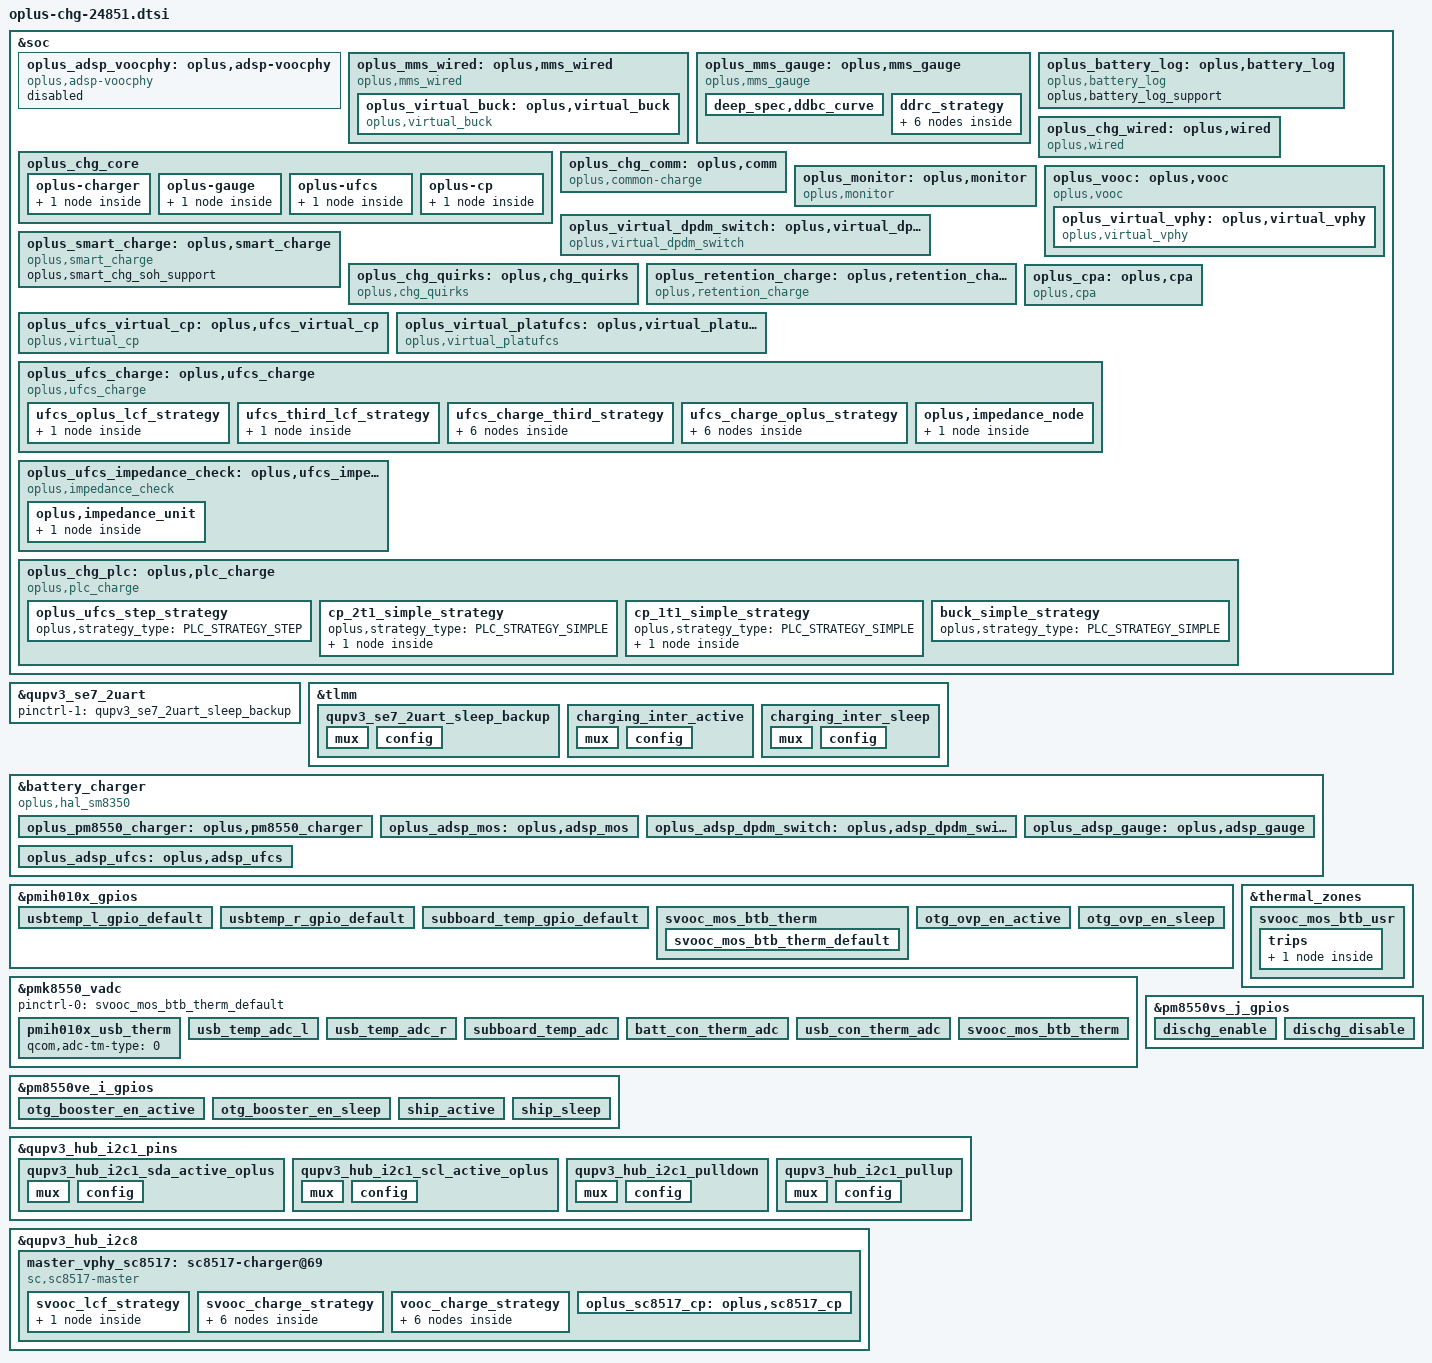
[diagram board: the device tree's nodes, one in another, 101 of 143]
//ifdef OPLUS_FEATURE_CHG_BASIC
//BSP.CHG.Basic, 2023/04/19, sjc Add for charging

#include "oplus-chg-8750.h.dtsi"

/*
 * NOTICE:
 * sector 1: wired charging
 * sector 2: ufcs
 * sector 3: pps
 */

//#ifdef OPLUS_FEATURE_CHG_BASIC /* BSP.CHG.Basic, 2023/04/19, sjc Add for wired charging */
//for wired charging config
&soc {
	oplus_adsp_voocphy: oplus,adsp-voocphy {
		status = "disabled";
		compatible = "oplus,adsp-voocphy";
	};

	oplus_mms_wired: oplus,mms_wired {
		compatible = "oplus,mms_wired";
		oplus,buck_ic = <&oplus_virtual_buck>;
		oplus,voocphy_ic = <&oplus_virtual_vphy>;

		oplus,adc_info_name = "855";
		oplus,topic-update-interval = <5000>;
		high-temp-scheme;

		oplus,support_usbtemp_protect_v2;
		oplus_spec,usbtemp_batt_temp_low = <50>;
		oplus_spec,usbtemp_batt_temp_high = <50>;
		oplus_spec,usbtemp_batt_temp_over_hot = <60>;
		oplus_spec,usbtemp_ntc_temp_low = <57>;
		oplus_spec,usbtemp_ntc_temp_high = <69>;
		oplus_spec,usbtemp_temp_gap_low_with_batt_temp = <7>;
		oplus_spec,usbtemp_temp_gap_with_batt_temp_in_over_hot = <15>;
		oplus_spec,usbtemp_temp_gap_high_with_batt_temp = <12>;
		oplus_spec,usbtemp_temp_gap_low_without_batt_temp = <12>;
		oplus_spec,usbtemp_temp_gap_high_without_batt_temp = <24>;
		oplus_spec,usbtemp_rise_fast_temp_low = <3>;
		oplus_spec,usbtemp_rise_fast_temp_high = <3>;
		oplus_spec,usbtemp_rise_fast_temp_count_low = <30>;
		oplus_spec,usbtemp_rise_fast_temp_count_high = <20>;
		oplus_spec,usbtemp_cool_down_ntc_low = <54>;
		oplus_spec,usbtemp_cool_down_ntc_high = <65>;
		oplus_spec,usbtemp_cool_down_gap_low = <12>;
		oplus_spec,usbtemp_cool_down_gap_high = <20>;
		oplus_spec,usbtemp_cool_down_recover_ntc_low = <48>;
		oplus_spec,usbtemp_cool_down_recover_ntc_high = <60>;
		oplus_spec,usbtemp_cool_down_recover_gap_low = <6>;
		oplus_spec,usbtemp_cool_down_recover_gap_high = <15>;
		oplus_spec,usbtemp_otg_cc_boot_current_limit = <2000>;

		oplus,series_batt_buck_eis_current_rate = <2>;

		oplus_virtual_buck: oplus,virtual_buck {
			compatible = "oplus,virtual_buck";
			oplus,buck_ic = <&oplus_pm8550_charger>;
			oplus,buck_ic_index = <0>;
			oplus,buck_ic_connect = <OPLUS_CHG_IC_CONNECT_PARALLEL>;
			oplus,main_charger = <1>;
			oplus,buck_ic_current_ratio = <100>;
			oplus,buck_ic_func_group = <&plat_pm8550_groups>;

			oplus,ic_type = <OPLUS_CHG_IC_VIRTUAL_BUCK>;
			oplus,ic_index = <0>;

			oplus,dischg-gpio = <&pm8550vs_j_gpios 6 0x00>;
			oplus,ship-gpio = <&pm8550ve_i_gpios 7 0x00>;
			oplus,usbtemp_conversion_ratio = <10>;

			pinctrl-names = "usbtemp_l_gpio_default", "usbtemp_r_gpio_default",
						"dischg_enable", "dischg_disable",
						"ship_active", "ship_sleep";
			pinctrl-0 = <&usbtemp_l_gpio_default>;
			pinctrl-1 = <&usbtemp_r_gpio_default>;
			pinctrl-2 = <&dischg_enable>;
			pinctrl-3 = <&dischg_disable>;
			pinctrl-4 = <&ship_active>;
			pinctrl-5 = <&ship_sleep>;

			io-channels = <&pmk8550_vadc PMIH010X_ADC5_GEN4_AMUX1_GPIO6_100K_PU>,
					      <&pmk8550_vadc PMIH010X_ADC5_GEN4_AMUX5_GPIO18_100K_PU>;
			io-channel-names = "usb_temp_adc_l", "usb_temp_adc_r";

			oplus,uart_tx-gpio = <&tlmm 62 0x00>;
			oplus,uart_rx-gpio = <&tlmm 63 0x00>;
		};
	};
	oplus_mms_gauge: oplus,mms_gauge {
		compatible = "oplus,mms_gauge";
		oplus,gauge_ic = <&oplus_virtual_gauge>;
		oplus,topic-update-interval = <5000>;
		oplus,support_subboard_ntc;
		oplus,fcl_support;
		oplus,fcl_index = <0>;
		oplus,vb_offset = <0>;

		deep_spec,support;
		deep_spec,uv_thr = <2750>;
		deep_spec,count_thr = <50>;
		deep_spec,vbat_soc = <80>;
		deep_spec,count_step = <0 10 0
					350 12 1
					450 15 2
					530 20 3>;

		deep_spec,term_coeff = <2900 600 0
					3000 650 0
					3010 650 0
					3050 750 0
					3100 800 0
					3110 800 0
					3150 900 0
					3160 900 0
					3200 1000 0
					3210 1000 0
					3260 1100 0>;
		deep_spec,ddrc_strategy_name = "ddrc_curve_v2";
		deep_spec,volt_step = <20>;
		deep_spec,ddbc_curve {
			oplus,temp_type = <OPLUS_STRATEGY_USE_BATT_TEMP>;
			oplus,temp_range = <(-100) 0 200>;
			deep_spec,ddbc_temp_cold = <500 3250 5
						   10000 3200 2>;
			deep_spec,ddbc_temp_cool = <500 3250 5
						   10000 3200 2>;
			deep_spec,ddbc_temp_normal = <500 3250 5
						   10000 3200 2>;
			deep_spec,ddbc_temp_warm = <500 3250 5
						   10000 3200 2>;
		};
		ddrc_strategy {
			oplus,temp_type = <OPLUS_STRATEGY_USE_BATT_TEMP>;
			oplus,ratio_range = <20 30 50 70 90>;
			oplus,temp_range = <(-100) 0 100 200 350>;
			strategy_ratio_range_min {
				strategy_temp_0 =	<0 2753 3000 0
							300 2910 3100 1
							700 3010 3150 2
							1100 3061 3160 3
							1500 3111 3210 4
							1900 3161 3260 5>;
				strategy_temp_1 =	<0 2752 3100 0
							400 2910 3100 1
							900 3010 3150 2
							1400 3061 3160 3
							1900 3111 3210 4
							2400 3161 3260 5>;
				strategy_temp_2 =	<0 2752 3100 0
							400 2910 3100 1
							900 3010 3150 2
							1400 3061 3160 3
							1900 3111 3210 4
							2400 3161 3260 5>;
				strategy_temp_3 =	<0 2751 2950 0
							400 2911 3000 1
							900 3000 3010 2
							1400 3060 3110 3
							1900 3110 3160 4
							2400 3160 3210 5>;
				strategy_temp_4 =	<0 2750 2900 0
							400 2900 2910 1
							900 3000 3010 2
							1400 3050 3050 3
							1900 3100 3100 4
							2400 3150 3150 5>;
				strategy_temp_5 =	<0 2750 2900 0
							400 2900 2910 1
							900 3000 3010 2
							1400 3050 3050 3
							1900 3100 3100 4
							2400 3150 3150 5>;
			};
			strategy_ratio_range_low {
				strategy_temp_0 =	<0 2753 3000 0
							250 2910 3100 1
							550 3010 3150 2
							850 3110 3160 3
							1150 3160 3210 4
							1450 3210 3260 5>;
				strategy_temp_1 =	<0 2752 3100 0
							300 2910 3100 1
							700 3010 3150 2
							1100 3061 3160 3
							1500 3111 3210 4
							1900 3161 3260 5>;
				strategy_temp_2 =	<0 2752 3100 0
							300 2910 3100 1
							700 3010 3150 2
							1100 3061 3160 3
							1500 3111 3210 4
							1900 3161 3260 5>;
				strategy_temp_3 =	<0 2751 2950 0
							300 2911 3000 1
							700 3000 3010 2
							1100 3060 3110 3
							1500 3110 3160 4
							1900 3160 3210 5>;
				strategy_temp_4 =	<0 2750 2900 0
							300 2900 2910 1
							700 3000 3010 2
							1100 3050 3050 3
							1500 3100 3100 4
							1900 3150 3150 5>;
				strategy_temp_5 =	<0 2750 2900 0
							300 2900 2910 1
							700 3000 3010 2
							1100 3050 3050 3
							1500 3100 3100 4
							1900 3150 3150 5>;
			};
			strategy_ratio_range_mid_low {
				strategy_temp_0 =	<0 2753 3000 0
							100 2910 3100 1
							250 3010 3150 2
							400 3110 3160 3
							550 3160 3210 4
							700 3210 3260 5>;
				strategy_temp_1 =	<0 2752 3100 0
							100 2910 3100 1
							300 3010 3150 2
							600 3061 3160 3
							900 3111 3210 4
							1200 3161 3260 5>;
				strategy_temp_2 =	<0 2752 3100 0
							100 2910 3100 1
							300 3010 3150 2
							600 3061 3160 3
							900 3111 3210 4
							1200 3161 3260 5>;
				strategy_temp_3 =	<0 2751 2950 0
							100 2911 3000 1
							300 3000 3010 2
							600 3060 3110 3
							900 3110 3160 4
							1200 3160 3210 5>;
				strategy_temp_4 =	<0 2750 2900 0
							100 2900 2910 1
							300 3000 3010 2
							600 3050 3050 3
							900 3100 3100 4
							1200 3150 3150 5>;
				strategy_temp_5 =	<0 2750 2900 0
							100 2900 2910 1
							300 3000 3010 2
							600 3050 3050 3
							900 3100 3100 4
							1200 3150 3150 5>;
			};
			strategy_ratio_range_mid {
				strategy_temp_0 =	<0 2753 3000 0
							50 2910 3100 1
							150 3010 3150 2
							300 3110 3160 3
							450 3160 3210 4
							600 3210 3260 5>;
				strategy_temp_1 =	<0 2752 3100 0
							50 2910 3100 1
							150 3010 3150 2
							350 3061 3160 3
							550 3111 3210 4
							750 3161 3260 5>;
				strategy_temp_2 =	<0 2752 3100 0
							50 2910 3100 1
							150 3010 3150 2
							350 3061 3160 3
							550 3111 3210 4
							750 3161 3260 5>;
				strategy_temp_3 =	<0 2751 2950 0
							50 2911 3000 1
							150 3000 3010 2
							350 3060 3110 3
							550 3110 3160 4
							750 3160 3210 5>;
				strategy_temp_4 =	<0 2750 2900 0
							50 2900 2910 1
							150 3000 3010 2
							350 3050 3050 3
							550 3100 3100 4
							750 3150 3150 5>;
				strategy_temp_5 =	<0 2750 2900 0
							50 2900 2910 1
							150 3000 3010 2
							350 3050 3050 3
							550 3100 3100 4
							750 3150 3150 5>;
			};
			strategy_ratio_range_mid_high {
				strategy_temp_0 =	<0 2753 3000 0
							50 2910 3100 1
							150 3010 3150 2
							250 3110 3160 3
							350 3160 3210 4
							450 3210 3260 5>;
				strategy_temp_1 =	<0 2752 3100 0
							50 2910 3100 1
							150 3010 3150 2
							250 3061 3160 3
							350 3111 3210 4
							450 3161 3260 5>;
				strategy_temp_2 =	<0 2752 3100 0
							50 2910 3100 1
							150 3010 3150 2
							250 3061 3160 3
							350 3111 3210 4
							450 3161 3260 5>;
				strategy_temp_3 =	<0 2751 2950 0
							50 2911 3000 1
							150 3000 3010 2
							250 3060 3110 3
							350 3110 3160 4
							450 3160 3210 5>;
				strategy_temp_4 =	<0 2750 2900 0
							50 2900 2910 1
							150 3000 3010 2
							250 3100 3100 3
							350 3150 3150 4
							450 3200 3200 5>;
				strategy_temp_5 =	<0 2750 2900 0
							50 2900 2910 1
							150 3000 3010 2
							250 3100 3100 3
							350 3150 3150 4
							450 3200 3200 5>;
			};
			strategy_ratio_range_high {
				strategy_temp_0 =	<0 2753 3000 0
							50 2910 3100 1
							150 3010 3150 2
							250 3110 3160 3
							350 3160 3210 4
							450 3210 3260 5>;
				strategy_temp_1 =	<0 2752 3100 0
							50 2910 3100 1
							150 3010 3150 2
							250 3061 3160 3
							350 3111 3210 4
							450 3161 3260 5>;
				strategy_temp_2 =	<0 2752 3100 0
							50 2910 3100 1
							150 3010 3150 2
							250 3061 3160 3
							350 3111 3210 4
							450 3161 3260 5>;
				strategy_temp_3 =	<0 2751 2950 0
							50 2911 3000 1
							150 3000 3010 2
							250 3060 3110 3
							350 3110 3160 4
							450 3160 3210 5>;
				strategy_temp_4 =	<0 2750 2900 0
							50 2900 2910 1
							150 3000 3010 2
							250 3100 3100 3
							350 3150 3150 4
							450 3200 3200 5>;
				strategy_temp_5 =	<0 2750 2900 0
							50 2900 2910 1
							150 3000 3010 2
							250 3100 3100 3
							350 3150 3150 4
							450 3200 3200 5>;
			};
		};
	};
};

&soc {
	oplus_chg_core: oplus_chg_core {
		oplus,chg_framework_v2;
		oplus,battery_type_by_smem;
		oplus,smart_charging_screenoff;
		oplus,chg_spec_version = <OPLUS_CHG_SPEC_VER_V3P7>;
		oplus,common-charge-icl-support;

		oplus-charger {
			plat_pm8550_groups: oplus,plat_pm8550-groups {
				functions = <
					OPLUS_IC_FUNC_INIT
					OPLUS_IC_FUNC_EXIT
					OPLUS_IC_FUNC_REG_DUMP
					OPLUS_IC_FUNC_SMT_TEST
					OPLUS_IC_FUNC_BUCK_INPUT_PRESENT
					OPLUS_IC_FUNC_BUCK_INPUT_SUSPEND
					OPLUS_IC_FUNC_BUCK_INPUT_IS_SUSPEND
					OPLUS_IC_FUNC_BUCK_OUTPUT_SUSPEND
					OPLUS_IC_FUNC_BUCK_OUTPUT_IS_SUSPEND
					OPLUS_IC_FUNC_BUCK_GET_CC_ORIENTATION
					OPLUS_IC_FUNC_BUCK_GET_CHARGER_TYPE
					OPLUS_IC_FUNC_BUCK_RERUN_BC12
					OPLUS_IC_FUNC_BUCK_QC_DETECT_ENABLE
					OPLUS_IC_FUNC_BUCK_SHIPMODE_ENABLE
					OPLUS_IC_FUNC_BUCK_SET_QC_CONFIG
					OPLUS_IC_FUNC_BUCK_SET_PD_CONFIG
					OPLUS_IC_FUNC_GET_SHUTDOWN_SOC
					OPLUS_IC_FUNC_BACKUP_SOC
					OPLUS_IC_FUNC_GET_TYPEC_MODE
					OPLUS_IC_FUNC_BUCK_SET_ICL
					OPLUS_IC_FUNC_BUCK_GET_ICL
					OPLUS_IC_FUNC_BUCK_SET_FCC
					OPLUS_IC_FUNC_BUCK_SET_FV
					OPLUS_IC_FUNC_BUCK_SET_ITERM
					OPLUS_IC_FUNC_BUCK_SET_RECHG_VOL
					OPLUS_IC_FUNC_BUCK_GET_INPUT_CURR
					OPLUS_IC_FUNC_BUCK_GET_INPUT_VOL
					OPLUS_IC_FUNC_GET_CHARGER_CYCLE
					OPLUS_IC_FUNC_OTG_BOOST_ENABLE
					OPLUS_IC_FUNC_SET_OTG_BOOST_CURR_LIMIT
					OPLUS_IC_FUNC_BUCK_GET_VBUS_COLLAPSE_STATUS
					OPLUS_IC_FUNC_GET_OTG_ENABLE
					OPLUS_IC_FUNC_SET_OTG_SWITCH_STATUS
					OPLUS_IC_FUNC_GET_OTG_SWITCH_STATUS
					OPLUS_IC_FUNC_GET_OTG_ONLINE_STATUS
					OPLUS_IC_FUNC_BUCK_GET_HW_DETECT
					OPLUS_IC_FUNC_VOOCPHY_SET_MATCH_TEMP
					OPLUS_IC_FUNC_IS_OPLUS_SVID
					OPLUS_IC_FUNC_BUCK_SET_VINDPM
					OPLUS_IC_FUNC_WLS_BOOST_ENABLE
					OPLUS_IC_FUNC_SET_WLS_BOOST_VOL
					OPLUS_IC_FUNC_SET_WLS_BOOST_CURR_LIMIT
					OPLUS_IC_FUNC_BUCK_WLS_INPUT_SUSPEND
					OPLUS_IC_FUNC_BUCK_SET_WLS_ICL
					OPLUS_IC_FUNC_BUCK_GET_WLS_ICL
					OPLUS_IC_FUNC_BUCK_GET_WLS_INPUT_CURR
					OPLUS_IC_FUNC_BUCK_GET_WLS_INPUT_VOL
					OPLUS_IC_FUNC_BUCK_WLS_AICL_ENABLE
					OPLUS_IC_FUNC_BUCK_WLS_AICL_RERUN
					OPLUS_IC_FUNC_BUCK_DIS_INSERT_DETECT
					OPLUS_IC_FUNC_GET_TYPEC_ROLE
					OPLUS_IC_FUNC_SET_TYPEC_MODE
					OPLUS_IC_FUNC_BUCK_GET_USB_BTB_TEMP
					OPLUS_IC_FUNC_BUCK_GET_BATT_BTB_TEMP
					OPLUS_IC_FUNC_BUCK_GET_USB_AICL_ENHANCE
					OPLUS_IC_FUNC_BUCK_SET_AICL_POINT
					OPLUS_IC_FUNC_BUCK_ITEM_CHECK
					OPLUS_IC_FUNC_GET_SOURCE_PDO
					OPLUS_IC_FUNC_BUCK_GET_VDM_INFO
					OPLUS_IC_FUNC_BUCK_SEND_GET_SINK_CAP
				>;
				virqs = <
					OPLUS_IC_VIRQ_ERR
					OPLUS_IC_VIRQ_CC_DETECT
					OPLUS_IC_VIRQ_PLUGIN
					OPLUS_IC_VIRQ_CC_CHANGED
					OPLUS_IC_VIRQ_SUSPEND_CHECK
					OPLUS_IC_VIRQ_CHG_TYPE_CHANGE
					OPLUS_IC_VIRQ_OTG_ENABLE
					OPLUS_IC_VIRQ_SVID
					OPLUS_IC_VIRQ_POWER_CHANGED
				>;
			};
		};

		oplus-gauge {
			oplus_adsp_gauge_groups: oplus,oplus_adsp_gauge_groups {
				functions = <
					OPLUS_IC_FUNC_INIT
					OPLUS_IC_FUNC_EXIT
					OPLUS_IC_FUNC_REG_DUMP
					OPLUS_IC_FUNC_SMT_TEST
					OPLUS_IC_FUNC_GAUGE_GET_SUBBOARD_TEMP
				>;
				virqs = <
					OPLUS_IC_VIRQ_ERR
				>;
			};
		};

		oplus-ufcs {
			adsp_ufcs_groups: oplus,ufcs_groups {
				functions = <
					OPLUS_IC_FUNC_INIT
					OPLUS_IC_FUNC_EXIT
					OPLUS_IC_FUNC_REG_DUMP
					OPLUS_IC_FUNC_SMT_TEST
					OPLUS_IC_FUNC_UFCS_HANDSHAKE
					OPLUS_IC_FUNC_UFCS_PDO_SET
					OPLUS_IC_FUNC_UFCS_HARD_RESET
					OPLUS_IC_FUNC_UFCS_EXIT
					OPLUS_IC_FUNC_UFCS_CONFIG_WD
					OPLUS_IC_FUNC_UFCS_GET_DEV_INFO
					OPLUS_IC_FUNC_UFCS_GET_ERR_INFO
					OPLUS_IC_FUNC_UFCS_GET_SRC_INFO
					OPLUS_IC_FUNC_UFCS_GET_CABLE_INFO
					OPLUS_IC_FUNC_UFCS_GET_PDO_INFO
					OPLUS_IC_FUNC_UFCS_VERIFY_ADAPTER
					OPLUS_IC_FUNC_UFCS_GET_POWER_CHANGE_INFO
					OPLUS_IC_FUNC_UFCS_GET_EMARK_INFO
					OPLUS_IC_FUNC_UFCS_GET_POWER_INFO_EXT
					OPLUS_IC_FUNC_UFCS_IS_TEST_MODE
				>;
				virqs = <
					OPLUS_IC_VIRQ_ERR
					OPLUS_IC_VIRQ_ONLINE
					OPLUS_IC_VIRQ_OFFLINE
				>;
			};
		};

		oplus-cp {
			adsp_mos_groups: oplus,mos_groups {
			functions = <
					OPLUS_IC_FUNC_INIT
					OPLUS_IC_FUNC_EXIT
					OPLUS_IC_FUNC_CP_GET_TEMP
				>;
				virqs = <
					OPLUS_IC_VIRQ_ERR
					OPLUS_IC_VIRQ_ONLINE
					OPLUS_IC_VIRQ_OFFLINE
				>;
			};
		};
	};
};

&qupv3_se7_2uart {
	pinctrl-1 = <&qupv3_se7_2uart_sleep_backup>;
	status = "okay";
};

&tlmm {
	qupv3_se7_2uart_sleep_backup:qupv3_se7_2uart_sleep_backup {
		mux {
			pins = "gpio62", "gpio63";
			function = "gpio";
		};

		config {
			pins = "gpio62", "gpio63";
			drive-strength = <2>;
			bias-disable;
			input-enable;
		};
	};
};

&battery_charger {
	//for oplus chg framework:
	oplus,chg_ops = "plat-pmic";
	qcom,pmic_ftm_vph = "/sys/bus/spmi/drivers/pmic-spmi/0-00/c42d000.qcom,spmi:qcom,pmk8550@0:vadc@9000/iio:device0/in_voltage_pmih010x_vph_pwr_input";
	qcom,pmic_ftm_vbat = "/sys/bus/spmi/drivers/pmic-spmi/0-00/c42d000.qcom,spmi:qcom,pmk8550@0:vadc@9000/iio:device0/in_voltage_pmih010x_vbat_sns_qbg_input";
	oplus,usb_aicl_enhance;

	//qcom,otg-booster-en-gpio = <&pm8550ve_i_gpios 8 0x00>;
	//qcom,otg-ovp-en-gpio = <&pmih010x_gpios 11 0x00>;
	//oplus,wrx_otg_en-gpio = <&pm8550_gpios 1 0x00>;//wls nor OVP check
	//pinctrl-names = "otg_booster_en_active", "otg_booster_en_sleep",
	//		"otg_ovp_en_active", "otg_ovp_en_sleep",
	//		"subboard_temp_gpio_default";
	//pinctrl-0 = <&otg_booster_en_active>;
	//pinctrl-1 = <&otg_booster_en_sleep>;
	//pinctrl-2 = <&otg_ovp_en_active>;
	//pinctrl-3 = <&otg_ovp_en_sleep>;
	//pinctrl-4 = <&subboard_temp_gpio_default>;
	//pinctrl-5 = <&wrx_otg_en_active>;
	//pinctrl-6 = <&wrx_otg_en_sleep>;

};

&battery_charger {
	compatible = "oplus,hal_sm8350";
	//oplus,vphy_ic = <&oplus_adsp_voocphy>;
	oplus,voocphy_support;
	//oplus,vooc_project = <8>;
	oplus,voocphy_bidirect_cp_support;
	oplus,batt_num = <2>;
	oplus,otg_scheme = <0>;//0:cid 1:ccdetect_gpio 2:switch
	oplus,ufcs_run_check_support;

	oplus_pm8550_charger: oplus,pm8550_charger {
		oplus,ic_type = <OPLUS_CHG_IC_BUCK>;
		oplus,ic_index = <0>;
	};
	oplus_adsp_mos: oplus,adsp_mos {
		oplus,ic_type = <OPLUS_CHG_IC_CP>;
		oplus,ic_index = <0>;
		oplus,ic_func_group = <&adsp_mos_groups>;
	};
	oplus_adsp_dpdm_switch: oplus,adsp_dpdm_switch {
		oplus,ic_type = <OPLUS_CHG_IC_MISC>;
		oplus,ic_index = <0>;
	};
	oplus_adsp_gauge: oplus,adsp_gauge {
		oplus,ic_type = <OPLUS_CHG_IC_GAUGE>;
		oplus,ic_index = <0>;
	};
	oplus_adsp_ufcs: oplus,adsp_ufcs {
		oplus,ic_type = <OPLUS_CHG_IC_UFCS>;
		oplus,ic_index = <0>;
	};
};

&soc {
	oplus_battery_log: oplus,battery_log {
		compatible = "oplus,battery_log";

		oplus,battery_log_support;
	};

	oplus_chg_wired: oplus,wired {
		compatible = "oplus,wired";

		oplus,vooc-support;
		oplus,qc-curr-check-support;
		oplus_spec,vbatt_pdqc_to_5v_thr = <5100>;
		oplus_spec,vbatt_pdqc_to_9v_thr = <5000>;
		oplus_spec,pd-iclmax-ma = <2000>;
		oplus_spec,qc-iclmax-ma = <2000>;
		oplus_spec,non-standard-ibatmax-ma = <500>;
		oplus_spec,input-power-mw = <
			2500		/* OPLUS_WIRED_CHG_MODE_UNKNOWN */
			2500		/* OPLUS_WIRED_CHG_MODE_SDP */
			7500		/* OPLUS_WIRED_CHG_MODE_CDP */
			10000		/* OPLUS_WIRED_CHG_MODE_DCP */
			15000		/* OPLUS_WIRED_CHG_MODE_VOOC */
			18000		/* OPLUS_WIRED_CHG_MODE_QC */
			18000		/* OPLUS_WIRED_CHG_MODE_PD */
		>;
		oplus_spec,led_on-fccmax-ma = <0 722 2170 3618 4400 4400 4400 1000 0>;
		oplus_spec,fccmax-ma-lv = <
			0 521 2200 2200 2200 2200 2200 2200 0	/* OPLUS_WIRED_CHG_MODE_UNKNOWN */
			0 600  600  600  600  600  600  600 0	/* OPLUS_WIRED_CHG_MODE_SDP */
			0 722 1600 1600 1600 1600 1600 1600 0	/* OPLUS_WIRED_CHG_MODE_CDP */
			0 722 2170 2200 2200 2200 2200 2200 0	/* OPLUS_WIRED_CHG_MODE_DCP */
			0 722 2170 3300 3300 3300 3300 3300 0	/* OPLUS_WIRED_CHG_MODE_VOOC */
			0 722 2170 3618 4400 4400 4400 4190 0	/* OPLUS_WIRED_CHG_MODE_QC */
			0 722 2170 3618 4400 4400 4400 4190 0	/* OPLUS_WIRED_CHG_MODE_PD */
		>;
		oplus_spec,fccmax-ma-hv = <
			0 521 1042 1563 2200 2200 2200 1000 0	/* OPLUS_WIRED_CHG_MODE_UNKNOWN */
			0 380  600  600  600  600  600  600  0	/* OPLUS_WIRED_CHG_MODE_SDP */
			0 380  722 1446 1600 1600 1600 1000 0	/* OPLUS_WIRED_CHG_MODE_CDP */
			0 380  722 1446 2170 2200 2200 1000 0	/* OPLUS_WIRED_CHG_MODE_DCP */
			0 380  722 1446 2170 3300 3300 1000 0	/* OPLUS_WIRED_CHG_MODE_VOOC */
			0 380  722 1446 2170 3618 4400 1000 0	/* OPLUS_WIRED_CHG_MODE_QC */
			0 380  722 1446 2170 3618 4400 1000 0	/* OPLUS_WIRED_CHG_MODE_PD */
		>;

		oplus_spec,cool_down_sale_pdqc_vol_mv = <9000>;
		oplus_spec,cool_down_sale_pdqc_curr_ma = <1200>;
		oplus_spec,cool_down_pdqc_vol_mv = <9000 9000 9000>;
		oplus_spec,cool_down_pdqc_curr_ma = <1200 1500 2000>;
		oplus_spec,cool_down_vooc_curr_ma = <1500 1500 2000 2500 3000 3500>;
		oplus_spec,cool_down_normal_curr_ma = <1200 1500 2000>;

		oplus_spec,vbus_ov_thr_mv = <11000 11000>;
		oplus_spec,vbus_uv_thr_mv = <4300 4300>;

		/* first data is strategy used temp type */
		oplus,vooc_strategy_name = "cgcl";
		oplus,vooc_strategy_data = <OPLUS_STRATEGY_USE_BATT_TEMP
					    0   350 3000 1 0
					    330 370 3000 2 0
					    350 440 2200 2 1>;
	};

	oplus_chg_comm: oplus,comm {
		compatible = "oplus,common-charge";
		oplus_spec,dec_step = <20>;
		oplus_spec,dec-vol-cc-full-thr = <0 200 400 600 800 1000>;
		oplus_spec,dec-vol-fv-full-mv = <0 20 40 40 60 60>;
		oplus_spec,batt-them-thr = <(-100) 0 50 120 160 350 450 530>;
		oplus_spec,iterm-ma = <200>;
		oplus_spec,fv-mv = <4530 4530 4530 4530 4530 4530 4510 4130 4130>;
		oplus_spec,sw-fv-mv = <4470 4470 4470 4470 4470 4470 4450 4080 4080>;
		oplus_spec,hw-fv-inc-mv = <0 18 18 18 18 18 18 18 0>;
		oplus_spec,sw-over-fv-mv = <4528 4528 4528 4528 4528 4528 4508 4138 4138>;
		oplus_spec,sw-over-fv-dec-mv = <10>;
		oplus_spec,non-standard-sw-fv-mv = <3930>;
		oplus_spec,non-standard-fv-mv = <3980>;
		oplus_spec,non-standard-hw-fv-inc-mv = <18>;
		oplus_spec,non-standard-sw-over-fv-mv = <3990>;
		oplus_spec,non-standard-vbatdet-mv = <3680>;
		oplus_spec,wired-vbatdet-mv = <0 4220 4320 4420 4420 4420 4400 4030 0>;
		oplus_spec,fcc-gear-thr-mv = <3980>;
		oplus_spec,fcc-gear-shake-mv = <400 400 400 300 300 180 180 180 180>;
		oplus_spec,vbatt-ov-thr-mv = <4600>;
		oplus_spec,full_pre_ffc_judge;
		oplus_spec,full-pre-ffc-mv = <4515>;
		oplus_spec,ffc-temp-thr = <120 210 350 440>;
		oplus_spec,wired-ffc-step-max = <2>;
		oplus_spec,wired-ffc-fv-mv = <4610 4610>;

		oplus_spec,wired-ffc-fv-cutoff-mv = <4560 4545 4515
						     4540 4530 4500>;

		oplus_spec,removed_bat_decidegc = <390>;

		oplus_spec,wired-ffc-fcc-ma = <1100 1100 1100
					       700 700 700>;
		oplus_spec,wired-ffc-fcc-cutoff-ma = <400 400 400
						      200 200 200>;
		oplus_spec,drop_soc_2_temp_ladder = <(-50) 0 0 0 0 0 0 0 0 0>;
		oplus_spec,volt_diff_ladder_of_drop_soc_2 = <80 80 0 0 0 0 0 0 0 0>;
		oplus_spec,keep_soc_2_temp_ladder = <(-200) (-50) 0 0 0 0 0 0 0 0>;
		oplus_spec,volt_diff_ladder_of_keep_soc_2 = <10 20 30 0 0 0 0 0 0 0>;
		oplus_spec,back_rm_of_drop_soc_2 = <39>;
		oplus_spec,back_rm_of_drop_soc_1 = <0>;
		oplus_spec,load_current_of_drop_soc_2 = <1500>;
		oplus_spec,load_current_of_drop_soc_1 = <2000>;
		oplus_spec,current_limit_of_drop_soc_2 = <350>;
		oplus_spec,volt_of_fast_drop_soc_1 = <2750>;
		oplus_spec,support_uisoc_low_battery_control;

		oplus_spec,vbat_uv_thr_mv = <2750>;
		oplus_spec,vbat_charging_uv_thr_mv = <2650>;

		/*If use subboard NTC as battery temp, config it as 20, otherwise 0 */
		oplus_spec,tbatt_power_off_cali_temp = <0>;
		oplus,vooc_show_ui_soc_decimal;
		oplus_spec,poweroff_high_batt_temp = <720>;
		oplus_spec,poweroff_emergency_batt_temp = <770>;
		oplus,ui_soc_decimal_speedmin = <20>;

		oplus,gauge_stuck_jump_support;
		oplus,gauge_stuck_threshold = <15>;
		oplus,gauge_stuck_time = <50>;

		oplus_spec,sw_check_full_cnt = <12>;

		oplus,ui_soc_2_voltage_comp_mv = <30>;
		oplus,chg_shutdown_max_mv = <3000>;

		oplus_spec,hw_iterm_support;
	};

	oplus_monitor: oplus,monitor {
		compatible = "oplus,monitor";
		oplus,topic-update-interval = <60000>;

		track,fast_chg_break_t_thd = <2500>;
		track,general_chg_break_t_thd = <300>;
		track,voocphy_type = <2>;
		track,wired_max_power = <120000>;
		track,wired_fast_chg_scheme = <0>;
		track,low_soc_monitor_ctrl;
		track,track_ver = <TRACK_VER_4_0>;
	};

	oplus_vooc: oplus,vooc {
		compatible = "oplus,vooc";
		oplus,vooc_ic = <&oplus_virtual_vphy>;

		oplus_spec,vooc_soc_range = <55 75 85>;
		oplus_spec,vooc_temp_range = <50 120 180 350 450>;

		oplus,vooc_data_width = <7>;
		oplus,vooc_curr_max = <CURR_LIMIT_7BIT_11_0A>;
		oplus,support_vooc_by_normal_charger_path;
		oplus,vooc_project = <14>;
		oplus,vooc_power_max_w = <120>;
		oplus,voocphy_support = <2>;
		oplus,support_fake_vooc_check;
		oplus,subboard_ntc_abnormal_current = <4000>;
		oplus,smart_chg_bcc_support;

		oplus,abnormal_adapter_current = <CURR_LIMIT_7BIT_11_0A CURR_LIMIT_7BIT_11_0A
						CURR_LIMIT_7BIT_5_0A CURR_LIMIT_7BIT_5_0A
						CURR_LIMIT_7BIT_4_0A CURR_LIMIT_7BIT_4_0A
						CURR_LIMIT_7BIT_3_0A CURR_LIMIT_7BIT_3_0A
						CURR_LIMIT_7BIT_2_0A CURR_LIMIT_7BIT_2_0A>;

		oplus,abnormal_over_80w_adapter_current = <CURR_LIMIT_7BIT_11_0A CURR_LIMIT_7BIT_11_0A
						CURR_LIMIT_7BIT_7_0A CURR_LIMIT_7BIT_7_0A
						CURR_LIMIT_7BIT_6_0A CURR_LIMIT_7BIT_6_0A
						CURR_LIMIT_7BIT_5_0A CURR_LIMIT_7BIT_5_0A
						CURR_LIMIT_7BIT_4_0A CURR_LIMIT_7BIT_4_0A
						CURR_LIMIT_7BIT_3_0A CURR_LIMIT_7BIT_3_0A
						CURR_LIMIT_7BIT_2_0A CURR_LIMIT_7BIT_2_0A>;

		oplus,general_strategy_name = "cgcl";
		oplus,general_strategy_data = < OPLUS_STRATEGY_USE_SHELL_TEMP
						0   390 CURR_LIMIT_7BIT_11_0A 1 0
						387 410 CURR_LIMIT_7BIT_9_5A 2 0
						407 420 CURR_LIMIT_7BIT_7_5A 3 1
						417 430 CURR_LIMIT_7BIT_6_0A 4 2
						427 433 CURR_LIMIT_7BIT_5_0A 5 3
						430 436 CURR_LIMIT_7BIT_4_0A 6 4
						433 436 CURR_LIMIT_7BIT_3_0A 6 5 >;

		oplus,plc_strategy-data = <&buck_simple_strategy &cp_2t1_simple_strategy &cp_1t1_simple_strategy>;
		oplus,plc_strategy-names = "default", "svooc", "vooc";

		oplus_virtual_vphy: oplus,virtual_vphy {
			compatible = "oplus,virtual_vphy";
			oplus,vphy_ic = <&master_vphy_sc8517>;
			oplus,dpdm_switch_ic = <&oplus_virtual_dpdm_switch>;

			oplus,ic_type = <OPLUS_CHG_IC_VIRTUAL_VPHY>;
			oplus,ic_index = <0>;
		};
	};

	oplus_virtual_dpdm_switch: oplus,virtual_dpdm_switch {
		compatible = "oplus,virtual_dpdm_switch";
		oplus,ic_type = <OPLUS_CHG_IC_MISC>;
		oplus,ic_index = <0>;
		oplus,use_audio_switch;
	};

	oplus_smart_charge: oplus,smart_charge {
		compatible = "oplus,smart_charge";
		oplus,smart_chg_soh_support;
	};
	oplus_chg_quirks: oplus,chg_quirks {
		compatible = "oplus,chg_quirks";
	};
	oplus_retention_charge: oplus,retention_charge {
		compatible = "oplus,retention_charge";
		oplus,topic-update-interval = <5000>;
		oplus,support_retention_name = "oplus_retention_quirks";
	};
};

&pmih010x_gpios {
	usbtemp_l_gpio_default: usbtemp_l_gpio_default {
		pins = "gpio6"; //GPIO 6
		function = "normal"; //normal
		bias-high-impedance; //DISABLE GPIO5 for ADC
		bias-disable;
	};
	usbtemp_r_gpio_default: usbtemp_r_gpio_default {
		pins = "gpio18"; //GPIO 18
		function = "normal"; //normal
		bias-high-impedance; //DISABLE GPIO10 for ADC
		bias-disable;
	};
	subboard_temp_gpio_default: subboard_temp_gpio_default {
		pins = "gpio12"; //GPIO 12
		function = "normal"; //normal
		bias-high-impedance; //DISABLE GPIO6 for ADC
		bias-disable;
	};
	svooc_mos_btb_therm {
		svooc_mos_btb_therm_default: svooc_mos_btb_therm_default {
			pins = "gpio15";
			function = "normal"; //normal
			bias-high-impedance;
			bias-disable;
		};
	};

};

&pmk8550_vadc {
	pinctrl-0 = <&svooc_mos_btb_therm_default>;
	pinctrl-names = "default";

    pmih010x_usb_therm { //for PMIH010X_ADC5_GEN4_AMUX_THM4_USB_THERM_100K_PU
		qcom,adc-tm-type = <0>;
	};

	usb_temp_adc_l {
		reg = <PMIH010X_ADC5_GEN4_AMUX1_GPIO6_100K_PU>;
		label = "usb_temp_adc_l";
		qcom,pre-scaling = <1 1>;
		qcom,hw-settle-time = <200>;
		qcom,adc5-gen4;
		qcom,scale-fn-type = <OPLUS_ADC_SCALE_HW_CALIB_DEFAULT>;
	};
	usb_temp_adc_r {
		reg = <PMIH010X_ADC5_GEN4_AMUX5_GPIO18_100K_PU>;
		label = "usb_temp_adc_r";
		qcom,pre-scaling = <1 1>;
		qcom,hw-settle-time = <200>;
		qcom,adc5-gen4;
		qcom,scale-fn-type = <OPLUS_ADC_SCALE_HW_CALIB_DEFAULT>;
	};

	subboard_temp_adc {
		reg = <PMIH010X_ADC5_GEN4_AMUX4_GPIO12_100K_PU>;
		label = "subboard_temp_adc";
		qcom,pre-scaling = <1 1>;
		qcom,ratiometric;
		qcom,hw-settle-time = <200>;
		qcom,adc5-gen4;
	};
	batt_con_therm_adc {
		reg = <PMIH010X_ADC5_GEN4_AMUX_THM1_BAT_THERM_100K_PU>;
		label = "batt_con_therm_adc";
		qcom,ratiometric;
		qcom,hw-settle-time = <200>;
		qcom,pre-scaling = <1 1>;
		qcom,adc-tm-type = <0>;
		qcom,adc5-gen4;
	};
	usb_con_therm_adc {
		reg = <PMIH010X_ADC5_GEN4_AMUX_THM4_USB_THERM_100K_PU>;
		label = "usb_con_therm_adc";
		qcom,ratiometric;
		qcom,hw-settle-time = <200>;
		qcom,pre-scaling = <1 1>;
		qcom,adc-tm-type = <0>;
		qcom,adc5-gen4;
	};
	svooc_mos_btb_therm {
		reg = <PMIH010X_ADC5_GEN4_AMUX2_BAT2_ID_100K_PU>;
		label = "svooc_mos_btb_therm";
		qcom,ratiometric;
		qcom,hw-settle-time = <200>;
		qcom,pre-scaling = <1 1>;
		qcom,adc-tm-type = <1>;
		qcom,adc5-gen4;
	};
};

&thermal_zones {
	svooc_mos_btb_usr {
		polling-delay-passive = <0>;
		polling-delay = <0>;
		thermal-sensors = <&pmk8550_vadc PMIH010X_ADC5_GEN4_AMUX2_BAT2_ID_100K_PU>;
		trips {
			active-config0 {
				temperature = <125000>;
				hysteresis = <1000>;
				type = "passive";
			};
		};
	};
};

&battery_charger {
	io-channels	= <&pmk8550_vadc PMIH010X_ADC5_GEN4_AMUX1_GPIO6_100K_PU>,
					<&pmk8550_vadc PMIH010X_ADC5_GEN4_AMUX5_GPIO18_100K_PU>,
					<&pmk8550_vadc PMIH010X_ADC5_GEN4_AMUX4_GPIO12_100K_PU>,
					<&pmk8550_vadc PMIH010X_ADC5_GEN4_AMUX_THM1_BAT_THERM_100K_PU>,
					<&pmk8550_vadc PMIH010X_ADC5_GEN4_AMUX_THM4_USB_THERM_100K_PU>,
					<&pmk8550_vadc PMIH010X_ADC5_GEN4_AMUX2_BAT2_ID_100K_PU>;
	io-channel-names = "usb_temp_adc_l", "usb_temp_adc_r", "subboard_temp_adc",
			   "batt_con_therm_adc", "usb_con_therm_adc", "svooc_mos_btb_therm";
};

&pm8550vs_j_gpios {
	dischg_enable: dischg_enable {
		pins = "gpio6";
		function = "normal";
		bias-disable;
		power-source = <0>;
		output-high;
		qcom,drive-strength = <3>;
	};
	dischg_disable: dischg_disable {
		pins = "gpio6";
		function = "normal";
		bias-disable;
		power-source = <0>;
		output-low;
		qcom,drive-strength = <3>;
	};
};

&pm8550ve_i_gpios {
	otg_booster_en_active: otg_booster_en_active {
		pins = "gpio8";
		function = "normal";
		bias-disable;
		power-source = <0>;
		output-high;
		qcom,drive-strength = <3>;
	};
	otg_booster_en_sleep: otg_booster_en_sleep {
		pins = "gpio8";
		function = "normal";
		bias-disable;
		power-source = <0>;
		output-low;
		qcom,drive-strength = <3>;
	};
	ship_active: ship_active {
		pins = "gpio7";
		function = "normal";
		bias-disable;
		power-source = <0>;
		output-high;
		qcom,drive-strength = <2>;
	};
	ship_sleep: ship_sleep {
		pins = "gpio7";
		function = "normal";
		bias-disable;
		power-source = <0>;
		output-low;
		qcom,drive-strength = <2>;
	};
};

&pmih010x_gpios {
	otg_ovp_en_active: otg_ovp_en_active {
		pins = "gpio11";
		function = "normal";
		bias-disable;
		power-source = <0>;
		output-high;
		qcom,drive-strength = <3>;
	};
	otg_ovp_en_sleep: otg_ovp_en_sleep {
		pins = "gpio11";
		function = "normal";
		bias-disable;
		power-source = <0>;
		output-low;
		qcom,drive-strength = <3>;
	};
};
&qupv3_hub_i2c1_pins {
	qupv3_hub_i2c1_sda_active_oplus: qupv3_hub_i2c1_sda_active_oplus {
		mux {
			pins = "gpio66";
			function = "i2chub0_se1_l0";
		};

		config {
			pins = "gpio66";
			drive-strength = <2>;
			bias-pull-up;
		};
	};

	qupv3_hub_i2c1_scl_active_oplus: qupv3_hub_i2c1_scl_active_oplus {
		mux {
			pins = "gpio67";
			function = "i2chub0_se1_l1";
		};

		config {
			pins = "gpio67";
			drive-strength = <2>;
			bias-pull-up;
		};
	};

	qupv3_hub_i2c1_pulldown: qupv3_hub_i2c1_pulldown {
		mux {
			pins = "gpio66", "gpio67";
			function = "gpio";
		};

		config {
			pins = "gpio66", "gpio67";
			drive-strength = <2>;
			bias-pull-down;
			output-low;
		};
	};

	qupv3_hub_i2c1_pullup: qupv3_hub_i2c1_pullup {
		mux {
			pins = "gpio66", "gpio67";
			function = "gpio";
		};

		config {
			pins = "gpio66", "gpio67";
			drive-strength = <2>;
			bias-pull-up;
			input-enable;
		};
	};
};

&tlmm {
	charging_inter_active: charging_inter_active {
		mux {
			pins = "gpio163";  /* SC8517_INT*/
			function = "gpio";
		};
		config {
			pins = "gpio163";
			bias-pull-up; /* NO pull */
			drive-strength = <2>; /* 2 MA */
			input-enable;
		};
	};

	charging_inter_sleep: charging_inter_sleep {
		mux {
			pins = "gpio163"; /* SC8517_INT*/
			function = "gpio";
		};
		config {
			pins = "gpio163";
			bias-pull-up; /* NO pull */
			drive-strength = <2>; /* 2 MA */
			input-enable;
		};
	};
};

&qupv3_hub_i2c8 {
	status = "okay";
	qcom,clk-freq-out = <400000>;
	pinctrl-names = "default", "sleep";
	pinctrl-0 = <&qupv3_hub_i2c8_sda_active>, <&qupv3_hub_i2c8_scl_active>;
	pinctrl-1 = <&qupv3_hub_i2c8_sleep>;

	master_vphy_sc8517: sc8517-charger@69{
		status = "okay";
		compatible = "sc,sc8517-master";
		reg = <0x69>;

		oplus,irq_gpio = <&tlmm 163 0x00>;
		oplus,v2x_volt_full_open_low;

		pinctrl-names = "charging_inter_active", "charging_inter_sleep";
		pinctrl-0 = <&charging_inter_active>;
		pinctrl-1 = <&charging_inter_sleep>;

		oplus,ic_type = <OPLUS_CHG_IC_VPHY>;
		oplus,ic_index = <0>;
		oplus,vooc-version = <VOOC_VERSION_5_0>;

		oplus_spec,external_gauge_support;
		oplus_spec,voocphy_bidirect_cp_support;
		oplus_spec,voocphy_current_default = <110>;
		oplus_spec,ap_control_allow;

		oplus_spec,svooc_cool_down_current_limit = <109 15 15 20 25 30 35 40 45 50 55 60 63 65 70 75 80 85 109>;
		oplus_spec,vooc_cool_down_current_limit = <61 20 20 20 30 40 50 60>;

		oplus_spec,vooc_little_cold_full_voltage = <4570>;
		oplus_spec,vooc_cool_full_voltage = <4570>;
		oplus_spec,vooc_little_cool_full_voltage = <4570>;
		oplus_spec,vooc_little_cool_high_full_voltage = <4570>;
		oplus_spec,vooc_warm_full_voltage = <4130>;
		oplus_spec,vooc_1time_full_voltage = <4580>;
		oplus_spec,vooc_ntime_full_voltage = <4570>;
		oplus_spec,full_voltage = < /* vol_1time vol_ntime */
					4580 4570 /* 0 ~ 5 */
					4580 4570 /* 5 ~ 12 */
					4580 4570 /* 12 ~ 16 */
					4580 4570 /* 16 ~ 20 */
					4585 4570 /* 20 ~ 35 */
					4580 4570 /* 35 ~ 44 */
					4140 4130 /* 44 ~ 51 */
					>;

		oplus_spec,vooc_multistep_initial_batt_temp = <1000>;
		oplus_spec,vooc_little_cool_temp = <160>;
		oplus_spec,vooc_little_cool_high_temp = <210>;
		oplus_spec,vooc_cool_temp = <120>;
		oplus_spec,vooc_little_cold_temp = <50>;
		oplus_spec,vooc_normal_low_temp = <350>;
		oplus_spec,vooc_strategy_normal_current = <100>;
		oplus_spec,vooc_normal_to_little_cool_current = <100>;
		oplus_spec,vooc_over_high_temp = <510>;
		oplus_spec,vooc_low_temp = <50>;
		oplus_spec,vooc_high_temp = <500>;
		oplus_spec,vooc_low_soc = <0>;
		oplus_spec,vooc_high_soc = <90>;
		oplus_spec,vooc_normal_high_temp = <440>;
		oplus_spec,vooc_warm_vol_thr = <4000>;
		oplus_spec,vooc_warm_soc_thr = <55>;
		oplus_spec,impedance_calculation_newmethod;
		oplus_spec,svooc_circuit_r_l = <0x18>;
		oplus_spec,svooc_circuit_r_h = <0x2>;/* 65 mR */

		oplus_spec,fastchg_timeout_time_init = <195940>;
		oplus_spec,voocphy_ibat_over_current = <12400>;
		oplus_spec,voocphy_cp_max_ibus = <12400>;
		oplus_spec,voocphy_svooc_cp_max_ibus = <3500>;
		oplus_spec,voocphy_vooc_cp_max_ibus = <3500>;
		oplus_spec,batt_pwd_curr_thd1 = <3000>;
		oplus_spec,batt_pwd_vol_thd1 = <4600>;

		oplus_spec,voocphy_freq_mincore = <940800>;
		oplus_spec,voocphy_freq_midcore = <1440000>;
		oplus_spec,voocphy_freq_maxcore = <1538000>;
		oplus_spec,voocphy_current_change_timeout = <100>;
		oplus_spec,copycat_vooc_support;

		oplus,abnormal_adapter_current = <CURR_LIMIT_7BIT_11_0A CURR_LIMIT_7BIT_11_0A
						  CURR_LIMIT_7BIT_5_0A CURR_LIMIT_7BIT_5_0A
						  CURR_LIMIT_7BIT_4_0A CURR_LIMIT_7BIT_4_0A
						  CURR_LIMIT_7BIT_3_0A CURR_LIMIT_7BIT_3_0A
						  CURR_LIMIT_7BIT_2_0A CURR_LIMIT_7BIT_2_0A>;

		oplus_spec,soc_range = <0 20 35 55 75 85 90>;

		svooc_batt_sys_curve = <1 1 0 1 1 1 0	// 11000mA
					1 0 1 1 1 0 0	// 4324mV
					0 0 1 0 1 0 0	// 2000mA
					1 1 1 0 1 1 1	// 4594mV
					0 0 0 1 1 0 0	// 1200mA
					1 1 1 0 1 1 1>; // 4594mV

		vooc_batt_sys_curve =  <0 1 0 1 1 0 1 	// 4500mA
					0 0 0 0 0 0 1	// 3414mV
					0 0 1 0 1 0 0	// 2000mA
					1 1 1 0 1 1 1	// 4594mV
					0 0 0 1 0 1 0	// 1000mA
					1 1 1 0 1 1 1>; // 4594mV

		svooc_lcf_strategy {
			oplus,temp_type = <OPLUS_STRATEGY_USE_SHELL_TEMP>;
			oplus,temp_range = <0 50 120 160 210 380 440>;

			strategy_temp_range_curves {
				strategy_temp_range_t0 =	<190 4530 0
								 165 4520 0
								 140 4510 0
								 115 4500 0
								 90 4490 1>;
				strategy_temp_range_t1 =	<500 4570 0
								 465 4565 0
								 430 4550 0
								 395 4540 0
								 360 4530 1>;
				strategy_temp_range_t2 =	<550 4570 0
								 505 4565 0
								 460 4550 0
								 415 4540 0
								 370 4530 1>;
				strategy_temp_range_t3 =	<600 4570 0
								 555 4565 0
								 510 4550 0
								 465 4540 0
								 420 4530 1>;
				strategy_temp_range_t4 =	<900 4570 0
								 850 4565 0
								 750 4550 0
								 650 4540 0
								 500 4530 1>;
				strategy_temp_range_t5 =	<1600 4564 0
								 1450 4558 0
								 1300 4535 0
								 1150 4535 0
								 1000 4510 1>;
			};
		};

		svooc_charge_strategy {
			strategy_soc_0_to_50 { /* 0 ~ 20 */
				strategy_temp_little_cold =	<4150 13 0 0 0
								4150 10 0 0 0
								4570  5 1 0 0>;
				strategy_temp_cool =		<4080 17 0 0 0
								4080 15 0 0 0
								4180 10 0 0 0
								4560  7 0 0 0
								4570  5 1 0 0>;
				strategy_temp_little_cool =	<4080 35 0 0 0
								4080 30 0 0 0
								4080 25 0 0 0
								4080 20 0 0 0
								4180 17 0 0 0
								4180 15 0 0 0
								4560 10 0 0 0
								4570  6 1 0 0>;
				strategy_temp_little_cool_high =	<4080 42 0 0 0
								4080 40 0 0 0
								4180 35 0 0 0
								4180 30 0 0 0
								4180 25 0 0 0
								4180 20 0 0 0
								4560 17 0 0 0
								4560 15 0 0 0
								4560 10 0 0 0
								4570  6 1 0 0>;
				strategy_temp_normal_low =	<4100 110 0 60 0
								4120 102 0 360 0
								4120 100 0 0 0
								4120 91 0 0 0
								4120 90 0 0 0
								4330 89 0 0 0
								4330 85 0 0 0
								4330 80 0 0 0
								4330 75 0 660 0
								4470 71 0 0 0
								4470 70 0 0 0
								4470 65 0 0 0
								4530 62 0 0 0
								4530 60 0 0 0
								4530 55 0 0 0
								4560 53 0 0 0
								4560 50 0 0 0
								4560 45 0 0 0
								4560 40 0 0 0
								4560 35 0 0 0
								4560 30 0 0 0
								4560 25 0 0 0
								4560 20 0 0 0
								4560 15 0 0 0
								4570 10 1 0 0>;
				strategy_temp_normal_high =	<4100 110 0 60 0
								4120 102 0 360 0
								4120 100 0 0 0
								4120 91 0 0 0
								4120 90 0 0 0
								4330 89 0 0 0
								4330 85 0 0 0
								4330 80 0 0 0
								4330 75 0 660 0
								4470 71 0 0 0
								4470 70 0 0 0
								4470 65 0 0 0
								4530 62 0 0 0
								4530 60 0 0 0
								4530 55 0 0 0
								4560 53 0 0 0
								4560 50 0 0 0
								4560 45 0 0 0
								4560 40 0 0 0
								4560 35 0 0 0
								4560 30 0 0 0
								4560 25 0 0 0
								4560 20 0 0 0
								4570 18 1 0 0>;
				strategy_temp_warm =		<4120 20 0 0 0
								4120 15 0 0 0
								4120 10 0 0 0
								4130  5 1 0 0>;
			};

			strategy_soc_0_to_50_mid { /* 21 ~ 35 */
				strategy_temp_little_cold =	<4150 13 0 0 0
								4150 10 0 0 0
								4570  5 1 0 0>;
				strategy_temp_cool =		<4080 17 0 0 0
								4080 15 0 0 0
								4180 10 0 0 0
								4560  7 0 0 0
								4570  5 1 0 0>;
				strategy_temp_little_cool =	<4080 35 0 0 0
								4080 30 0 0 0
								4080 25 0 0 0
								4080 20 0 0 0
								4180 17 0 0 0
								4180 15 0 0 0
								4560 10 0 0 0
								4570  6 1 0 0>;
				strategy_temp_little_cool_high =	<4080 42 0 0 0
								4080 40 0 0 0
								4180 35 0 0 0
								4180 30 0 0 0
								4180 25 0 0 0
								4180 20 0 0 0
								4560 17 0 0 0
								4560 15 0 0 0
								4560 10 0 0 0
								4570  6 1 0 0>;
				strategy_temp_normal_low =	<4100 110 0 60 0
								4120 102 0 360 0
								4120 100 0 0 0
								4120 91 0 0 0
								4120 90 0 0 0
								4330 89 0 0 0
								4330 85 0 0 0
								4330 80 0 0 0
								4330 75 0 660 0
								4470 71 0 0 0
								4470 70 0 0 0
								4470 65 0 0 0
								4530 62 0 0 0
								4530 60 0 0 0
								4530 55 0 0 0
								4560 53 0 0 0
								4560 50 0 0 0
								4560 45 0 0 0
								4560 40 0 0 0
								4560 35 0 0 0
								4560 30 0 0 0
								4560 25 0 0 0
								4560 20 0 0 0
								4560 15 0 0 0
								4570 10 1 0 0>;
				strategy_temp_normal_high =	<4100 110 0 60 0
								4120 102 0 360 0
								4120 100 0 0 0
								4120 91 0 0 0
								4120 90 0 0 0
								4330 89 0 0 0
								4330 85 0 0 0
								4330 80 0 0 0
								4330 75 0 660 0
								4470 71 0 0 0
								4470 70 0 0 0
								4470 65 0 0 0
								4530 62 0 0 0
								4530 60 0 0 0
								4530 55 0 0 0
								4560 53 0 0 0
								4560 50 0 0 0
								4560 45 0 0 0
								4560 40 0 0 0
								4560 35 0 0 0
								4560 30 0 0 0
								4560 25 0 0 0
								4560 20 0 0 0
								4570 18 1 0 0>;
				strategy_temp_warm =		<4120 20 0 0 0
								4120 15 0 0 0
								4120 10 0 0 0
								4130  5 1 0 0>;
			};

			strategy_soc_0_to_50_high { /* 36 ~ 55 */
				strategy_temp_little_cold =	<4150 10 0 0 0
								4570  5 1 0 0>;
				strategy_temp_cool =		<4080 17 0 0 0
								4080 15 0 0 0
								4180 10 0 0 0
								4560  7 0 0 0
								4570  5 1 0 0>;
				strategy_temp_little_cool =	<4080 35 0 0 0
								4080 30 0 0 0
								4080 25 0 0 0
								4080 20 0 0 0
								4180 17 0 0 0
								4180 15 0 0 0
								4560 10 0 0 0
								4570  6 1 0 0>;
				strategy_temp_little_cool_high =	<4080 42 0 0 0
								4080 40 0 0 0
								4180 35 0 0 0
								4180 30 0 0 0
								4180 25 0 0 0
								4180 20 0 0 0
								4560 17 0 0 0
								4560 15 0 0 0
								4560 10 0 0 0
								4570  6 1 0 0>;
				strategy_temp_normal_low =	<4100 110 0 60 0
								4120 102 0 360 0
								4120 100 0 0 0
								4120 91 0 0 0
								4120 90 0 0 0
								4330 89 0 0 0
								4330 85 0 0 0
								4330 80 0 0 0
								4330 75 0 660 0
								4470 71 0 0 0
								4470 70 0 0 0
								4470 65 0 0 0
								4530 62 0 0 0
								4530 60 0 0 0
								4530 55 0 0 0
								4560 53 0 0 0
								4560 50 0 0 0
								4560 45 0 0 0
								4560 40 0 0 0
								4560 35 0 0 0
								4560 30 0 0 0
								4560 25 0 0 0
								4560 20 0 0 0
								4560 15 0 0 0
								4570 10 1 0 0>;
				strategy_temp_normal_high =	<4100 110 0 60 0
								4120 102 0 360 0
								4120 100 0 0 0
								4120 91 0 0 0
								4120 90 0 0 0
								4330 89 0 0 0
								4330 85 0 0 0
								4330 80 0 0 0
								4330 75 0 660 0
								4470 71 0 0 0
								4470 70 0 0 0
								4470 65 0 0 0
								4530 62 0 0 0
								4530 60 0 0 0
								4530 55 0 0 0
								4560 53 0 0 0
								4560 50 0 0 0
								4560 45 0 0 0
								4560 40 0 0 0
								4560 35 0 0 0
								4560 30 0 0 0
								4560 25 0 0 0
								4560 20 0 0 0
								4570 18 1 0 0>;
				strategy_temp_warm =		<4120 20 0 0 0
								4120 15 0 0 0
								4120 10 0 0 0
								4130  5 1 0 0>;
			};

			strategy_soc_50_to_75 { /* 56 ~ 75 */
				strategy_temp_little_cold =	<4150 10 0 0 0
								4570  5 1 0 0>;
				strategy_temp_cool =		<4080 17 0 0 0
								4080 15 0 0 0
								4180 10 0 0 0
								4560  7 0 0 0
								4570  5 1 0 0>;
				strategy_temp_little_cool =	<4080 35 0 0 0
								4080 30 0 0 0
								4080 25 0 0 0
								4080 20 0 0 0
								4180 17 0 0 0
								4180 15 0 0 0
								4560 10 0 0 0
								4570  6 1 0 0>;
				strategy_temp_little_cool_high =	<4080 40 0 0 0
								4180 35 0 0 0
								4180 30 0 0 0
								4180 25 0 0 0
								4180 20 0 0 0
								4560 17 0 0 0
								4560 15 0 0 0
								4560 10 0 0 0
								4570  6 1 0 0>;
				strategy_temp_normal_low =	<4560 45 0 0 0
								4560 40 0 0 0
								4560 35 0 0 0
								4560 30 0 0 0
								4560 25 0 0 0
								4560 20 0 0 0
								4560 15 0 0 0
								4570 10 1 0 0>;
				strategy_temp_normal_high =	<4560 50 0 0 0
								4560 45 0 0 0
								4560 40 0 0 0
								4560 35 0 0 0
								4560 30 0 0 0
								4560 25 0 0 0
								4560 20 0 0 0
								4570 18 1 0 0>;
			};

			strategy_soc_75_to_85 { /* 76 ~ 85 */
				strategy_temp_little_cold =	<4150 10 0 0 0
								4570  5 1 0 0>;
				strategy_temp_cool =		<4080 17 0 0 0
								4080 15 0 0 0
								4180 10 0 0 0
								4560  7 0 0 0
								4570  5 1 0 0>;
				strategy_temp_little_cool =	<4080 30 0 0 0
								4080 25 0 0 0
								4080 20 0 0 0
								4180 17 0 0 0
								4180 15 0 0 0
								4560 10 0 0 0
								4570  6 1 0 0>;
				strategy_temp_little_cool_high =	<4180 30 0 0 0
								4180 25 0 0 0
								4180 20 0 0 0
								4560 17 0 0 0
								4560 15 0 0 0
								4560 10 0 0 0
								4570  6 1 0 0>;
				strategy_temp_normal_low =	<4560 35 0 0 0
								4560 30 0 0 0
								4560 25 0 0 0
								4560 20 0 0 0
								4560 15 0 0 0
								4570 10 1 0 0>;
				strategy_temp_normal_high =	<4560 35 0 0 0
								4560 30 0 0 0
								4560 25 0 0 0
								4560 20 0 0 0
								4570 18 1 0 0>;
			};

			strategy_soc_85_to_90 { /* 86 ~ 95 */
				strategy_temp_little_cold =	<4150 10 0 0 0
								4570  5 1 0 0>;
				strategy_temp_cool =		<4080 15 0 0 0
								4180 10 0 0 0
								4560  7 0 0 0
								4570  5 1 0 0>;
				strategy_temp_little_cool =	<4180 17 0 0 0
								4180 15 0 0 0
								4560 10 0 0 0
								4570  6 1 0 0>;
				strategy_temp_little_cool_high =	<4560 17 0 0 0
								4560 15 0 0 0
								4560 10 0 0 0
								4570  6 1 0 0>;
				strategy_temp_normal_low =	<4560 20 0 0 0
								4560 15 0 0 0
								4570 10 1 0 0>;
				strategy_temp_normal_high =	<4560 20 0 0 0
								4570 18 1 0 0>;
			};
		};

		vooc_charge_strategy {
			strategy_soc_0_to_50 {
				strategy_temp_little_cold =	<4430 20 1 0 0>;
				strategy_temp_cool =		<4420 30 0 0 0
								 4430 20 1 0 0>;
				strategy_temp_little_cool =	<4475 30 0 0 0
								 4480 20 1 0 0>;
				strategy_temp_little_cool_high =	<4475 30 0 0 0
								 4480 20 1 0 0>;
				strategy_temp_normal_low =	<4475 30 0 0 0
								 4480 20 1 0 0>;
				strategy_temp_normal_high =	<4475 30 0 0 0
								 4480 20 1 0 0>;
				strategy_temp_warm =		<4130 24 1 0 0>;
			};

			strategy_soc_0_to_50_mid {
				strategy_temp_little_cold =	<4430 20 1 0 0>;
				strategy_temp_cool =		<4420 30 0 0 0
								 4430 20 1 0 0>;
				strategy_temp_little_cool =	<4475 30 0 0 0
								 4480 20 1 0 0>;
				strategy_temp_little_cool_high =	<4475 30 0 0 0
								 4480 20 1 0 0>;
				strategy_temp_normal_low =	<4475 30 0 0 0
								 4480 20 1 0 0>;
				strategy_temp_normal_high =	<4475 30 0 0 0
								 4480 20 1 0 0>;
				strategy_temp_warm =		<4130 24 1 0 0>;
			};

			strategy_soc_0_to_50_high {
				strategy_temp_little_cold =	<4430 20 1 0 0>;
				strategy_temp_cool =		<4420 30 0 0 0
								 4430 20 1 0 0>;
				strategy_temp_little_cool =	<4475 30 0 0 0
								 4480 20 1 0 0>;
				strategy_temp_little_cool_high =	<4475 30 0 0 0
								 4480 20 1 0 0>;
				strategy_temp_normal_low =	<4475 30 0 0 0
								 4480 20 1 0 0>;
				strategy_temp_normal_high =	<4475 30 0 0 0
								 4480 20 1 0 0>;
				strategy_temp_warm =		<4130 24 1 0 0>;
			};

			strategy_soc_50_to_75 {
				strategy_temp_little_cold =	<4430 20 1 0 0>;
				strategy_temp_cool =		<4420 30 0 0 0
								 4430 20 1 0 0>;
				strategy_temp_little_cool =	<4475 30 0 0 0
								 4480 20 1 0 0>;
				strategy_temp_little_cool_high =	<4475 30 0 0 0
								 4480 20 1 0 0>;
				strategy_temp_normal_low =	<4475 30 0 0 0
								 4480 20 1 0 0>;
				strategy_temp_normal_high =	<4475 30 0 0 0
								 4480 20 1 0 0>;
				strategy_temp_warm =		<4130 24 1 0 0>;
			};

			strategy_soc_75_to_85 {
				strategy_temp_little_cold =	<4430 20 1 0 0>;
				strategy_temp_cool =		<4430 20 1 0 0>;
				strategy_temp_little_cool =	<4480 20 1 0 0>;
				strategy_temp_little_cool_high =	<4480 20 1 0 0>;
				strategy_temp_normal_low =	<4475 30 0 0 0
								 4480 20 1 0 0>;
				strategy_temp_normal_high =	<4475 30 0 0 0
								 4480 20 1 0 0>;
				strategy_temp_warm =		<4130 24 1 0 0>;
			};

			strategy_soc_85_to_90 {
				strategy_temp_little_cold =	<4430 20 1 0 0>;
				strategy_temp_cool =		<4430 20 1 0 0>;
				strategy_temp_little_cool =	<4480 20 1 0 0>;
				strategy_temp_little_cool_high =	<4480 20 1 0 0>;
				strategy_temp_normal_low =	<4480 20 1 0 0>;
				strategy_temp_normal_high =	<4480 20 1 0 0>;
				strategy_temp_warm =		<4130 24 1 0 0>;
			};
		};
		oplus_sc8517_cp: oplus,sc8517_cp {
			oplus,ic_type = <OPLUS_CHG_IC_CP>;
			oplus,ic_index = <0>;
		};
	};
};
//#endif OPLUS_FEATURE_CHG_BASIC /*for wired charging config*/
//#endif OPLUS_FEATURE_CHG_BASIC /*for wired charging config*/

//for ufcs config
&soc {
	oplus_cpa: oplus,cpa {
		compatible = "oplus,cpa";
		/* format: <protocol_type power_w> */
		oplus,protocol_list = <CHG_PROTOCOL_UFCS 120
				       CHG_PROTOCOL_VOOC 120
					CHG_PROTOCOL_PPS  55
					CHG_PROTOCOL_PD   18
				       CHG_PROTOCOL_QC   18>;
		oplus,default_protocol_list = <CHG_PROTOCOL_UFCS
					       CHG_PROTOCOL_VOOC
						CHG_PROTOCOL_PPS
						CHG_PROTOCOL_PD>;
	};

	oplus_ufcs_virtual_cp: oplus,ufcs_virtual_cp {
		compatible = "oplus,virtual_cp";

		oplus,ic_type = <OPLUS_CHG_IC_VIRTUAL_CP>;
		oplus,ic_index = <1>;

		oplus,cp_ic = <&oplus_sc8517_cp &oplus_adsp_mos>;
		oplus,input_curr_max_ma = <10950 0>;

		oplus,cp_ic_connect = <OPLUS_CHG_IC_CONNECT_PARALLEL>;
		oplus,main_cp = <0>;
	};

	oplus_virtual_platufcs: oplus,virtual_platufcs {
		compatible = "oplus,virtual_platufcs";

		oplus,ufcs_ic = <&oplus_adsp_ufcs>;
		oplus,ufcs_ic_index = <0>;
		oplus,ufcs_ic_connect = <OPLUS_CHG_IC_CONNECT_PARALLEL>;

		oplus,ufcs_ic_func_group = <&adsp_ufcs_groups>;
		oplus,ic_type = <OPLUS_CHG_IC_VIRTUAL_UFCS>;
		oplus,ic_index = <0>;
	};

	oplus_ufcs_charge: oplus,ufcs_charge {
		compatible = "oplus,ufcs_charge";
		oplus,ufcs_ic = <&oplus_virtual_platufcs>;
		oplus,cp_ic = <&oplus_ufcs_virtual_cp>;
		oplus,dpdm_switch_ic = <&oplus_adsp_dpdm_switch>;

		oplus,adsp_ufcs_project;
		oplus,ufcs_boot_time_retry = <10>;
		oplus,impedance_unit = <&oplus_ufcs_impedance_unit>;
		oplus,ufcs_need_reset_adapter;

		oplus,target_vbus_mv = <11000>;
		oplus,curr_max_ma = <10950>;
		oplus,curr_max_ma_percent = <3500 /* 75% ibus */
					    2000 /* 85% ibus */>;
		oplus,subboard_ntc_abnormal_current = <7300>;
		oplus,ufcs_warm_allow_vol = <4000>;
		oplus,ufcs_warm_allow_soc = <55>;
		oplus,ufcs_strategy_normal_current = <10950>;
		oplus,ufcs_over_high_or_low_current = <10950>;
		oplus,ufcs_timeout_third = <19594>;
		oplus,ufcs_timeout_oplus = <19594>;
		oplus,ufcs_ibat_over_third = <5400>;
		oplus,ufcs_ibat_over_oplus = <12350>;
		oplus,ufcs_ibus_over_oplus = <12350>;
		oplus,ufcs_full_cool_sw_vbat = <4570>;
		oplus,ufcs_full_normal_sw_vbat = <4570>;
		oplus,ufcs_full_normal_hw_vbat = <4580>;
		oplus,ufcs_full_ffc_vbat = <4570>;
		oplus,ufcs_full_warm_vbat = <4130>;
		oplus,ufcs_full_cool_sw_vbat_third = <4180>;
		oplus,ufcs_full_normal_sw_vbat_third= <4520>;
		oplus,ufcs_full_normal_hw_vbat_third = <4560>;
		oplus,ufcs_current_change_timeout = <100>;
		oplus,ufcs_strategy_batt_high_temp = <420 440 450 410 430 440>;
		oplus,ufcs_strategy_high_current = <6000 5000 3000 10900 6000 5000>;
		oplus,ufcs_little_cool_high_temp = <210>;
		oplus,curve_strategy_name = "pps_ufcs_curve_v2";
		oplus_spec,ufcs_high_temp = <500>;
		oplus_spec,ufcs_low_temp = <50>;
		oplus_spec,ufcs_high_soc = <90>;
		oplus_spec,ufcs_low_soc = <0>;
		oplus_spec,ufcs_high_soc_third = <85>;
		oplus,ufcs_charge_strategy_temp = <50 50 120 160 350 440 510>;

		oplus,plc_strategy-data = <&oplus_ufcs_step_strategy &cp_2t1_simple_strategy>;
		oplus,plc_strategy-names = "default", "third";

		/* Temperature control for power off charging */
		oplus,temperature_strategy_name = "cgcl";
		oplus,temperature_strategy_data = < OPLUS_STRATEGY_USE_SHELL_TEMP
						0   390 11000 1 0
						387 410 9100 2 0
						407 420 7500 3 1
						417 430 6000 4 2
						427 433 5000 5 3
						430 436 4000 6 4
						433 436 3000 6 5>;

		ufcs_oplus_lcf_strategy {
			oplus,temp_type = <OPLUS_STRATEGY_USE_SHELL_TEMP>;
			oplus,temp_range = <0 50 120 160 210 380 440>;

			strategy_temp_range_curves {
				strategy_temp_range_t0 =	<190 4530 0
								 165 4520 0
								 140 4510 0
								 115 4500 0
								 90 4490 1>;
				strategy_temp_range_t1 =	<500 4570 0
								 465 4565 0
								 430 4550 0
								 395 4540 0
								 360 4530 1>;
				strategy_temp_range_t2 =	<550 4570 0
								 505 4565 0
								 460 4550 0
								 415 4540 0
								 370 4530 1>;
				strategy_temp_range_t3 =	<600 4570 0
								 555 4565 0
								 510 4550 0
								 465 4540 0
								 420 4530 1>;
				strategy_temp_range_t4 =	<900 4570 0
								 850 4565 0
								 750 4550 0
								 650 4540 0
								 500 4530 1>;
				strategy_temp_range_t5 =	<1600 4564 0
								 1450 4558 0
								 1300 4535 0
								 1150 4535 0
								 1000 4510 1>;
			};
		};

		ufcs_third_lcf_strategy {
			oplus,temp_type = <OPLUS_STRATEGY_USE_SHELL_TEMP>;
			oplus,temp_range = <0 50 120 160 210 380 440>;

			strategy_temp_range_curves {
				strategy_temp_range_t0 =	<190 4530 0
								 165 4520 0
								 140 4510 0
								 115 4500 0
								 90 4490 1>;
				strategy_temp_range_t1 =	<500 4570 0
								 465 4565 0
								 430 4550 0
								 395 4540 0
								 360 4530 1>;
				strategy_temp_range_t2 =	<550 4570 0
								 505 4565 0
								 460 4550 0
								 415 4540 0
								 370 4530 1>;
				strategy_temp_range_t3 =	<600 4570 0
								 555 4565 0
								 510 4550 0
								 465 4540 0
								 420 4530 1>;
				strategy_temp_range_t4 =	<900 4570 0
								 850 4565 0
								 750 4550 0
								 650 4540 0
								 500 4530 1>;
				strategy_temp_range_t5 =	<1600 4564 0
								 1450 4558 0
								 1300 4535 0
								 1150 4535 0
								 1000 4510 1>;
			};
		};

		ufcs_charge_third_strategy {
			oplus,temp_type = <OPLUS_STRATEGY_USE_SHELL_TEMP>;
			oplus,soc_range = <0 20 35 55 75 85 90>;
			oplus,temp_range = <0 50 120 160 210 350 440 510>;

			strategy_soc_range_min {
				strategy_temp_little_cold =	<11000 4140 1300 0 0
								11000 4150 1000 1 0>;
				strategy_temp_cool =		<11000 4080 1700 0 0
								11000 4080 1500 0 0
								11000 4180 1000 1 0>;
				strategy_temp_little_cool =	<11000 4080 3500 0 0
								11000 4080 3000 0 0
								11000 4080 2500 0 0
								11000 4080 2000 0 0
								11000 4180 1700 0 0
								11000 4180 1500 0 0
								11000 4520 1000 1 0>;
				strategy_temp_little_cool_high = <11000 4080 4000 0 0
								11000 4180 3500 0 0
								11000 4180 3000 0 0
								11000 4180 2500 0 0
								11000 4180 2000 0 0
								11000 4510 1700 0 0
								11000 4510 1500 0 0
								11000 4520 1000 1 0>;
				strategy_temp_normal_low =	<11000 4510 4000 0 0
								11000 4510 3500 0 0
								11000 4510 3000 0 0
								11000 4510 2500 0 0
								11000 4510 2000 0 0
								11000 4510 1500 0 0
								11000 4520 1000 1 0>;
				strategy_temp_normal_high =	<11000 4490 4000 0 0
								11000 4490 3500 0 0
								11000 4490 3000 0 0
								11000 4490 2500 0 0
								11000 4490 2000 0 0
								11000 4490 1500 0 0
								11000 4500 1000 1 0>;
				strategy_temp_warm =		<11000 4120 2000 0 0
								11000 4120 1500 0 0
								11000 4130 1000 1 0>;
			};
			strategy_soc_range_low {
				strategy_temp_little_cold =	<11000 4140 1300 0 0
								11000 4150 1000 1 0>;
				strategy_temp_cool =		<11000 4080 1700 0 0
								11000 4080 1500 0 0
								11000 4180 1000 1 0>;
				strategy_temp_little_cool =	<11000 4080 3500 0 0
								11000 4080 3000 0 0
								11000 4080 2500 0 0
								11000 4080 2000 0 0
								11000 4180 1700 0 0
								11000 4180 1500 0 0
								11000 4520 1000 1 0>;
				strategy_temp_little_cool_high = <11000 4080 4000 0 0
								11000 4180 3500 0 0
								11000 4180 3000 0 0
								11000 4180 2500 0 0
								11000 4180 2000 0 0
								11000 4510 1700 0 0
								11000 4510 1500 0 0
								11000 4520 1000 1 0>;
				strategy_temp_normal_low =	<11000 4510 4000 0 0
								11000 4510 3500 0 0
								11000 4510 3000 0 0
								11000 4510 2500 0 0
								11000 4510 2000 0 0
								11000 4510 1500 0 0
								11000 4520 1000 1 0>;
				strategy_temp_normal_high =	<11000 4490 4000 0 0
								11000 4490 3500 0 0
								11000 4490 3000 0 0
								11000 4490 2500 0 0
								11000 4490 2000 0 0
								11000 4490 1500 0 0
								11000 4500 1000 1 0>;
				strategy_temp_warm =		<11000 4120 2000 0 0
								11000 4120 1500 0 0
								11000 4130 1000 1 0>;
			};
			strategy_soc_range_mid_low {
				strategy_temp_little_cold =	<11000 4140 1300 0 0
								11000 4150 1000 1 0>;
				strategy_temp_cool =		<11000 4080 1700 0 0
								11000 4080 1500 0 0
								11000 4180 1000 1 0>;
				strategy_temp_little_cool =	<11000 4080 3500 0 0
								11000 4080 3000 0 0
								11000 4080 2500 0 0
								11000 4080 2000 0 0
								11000 4180 1700 0 0
								11000 4180 1500 0 0
								11000 4520 1000 1 0>;
				strategy_temp_little_cool_high = <11000 4080 4000 0 0
								11000 4180 3500 0 0
								11000 4180 3000 0 0
								11000 4180 2500 0 0
								11000 4180 2000 0 0
								11000 4510 1700 0 0
								11000 4510 1500 0 0
								11000 4520 1000 1 0>;
				strategy_temp_normal_low =	<11000 4510 4000 0 0
								11000 4510 3500 0 0
								11000 4510 3000 0 0
								11000 4510 2500 0 0
								11000 4510 2000 0 0
								11000 4510 1500 0 0
								11000 4520 1000 1 0>;
				strategy_temp_normal_high =	<11000 4490 4000 0 0
								11000 4490 3500 0 0
								11000 4490 3000 0 0
								11000 4490 2500 0 0
								11000 4490 2000 0 0
								11000 4490 1500 0 0
								11000 4500 1000 1 0>;
				strategy_temp_warm =		<11000 4120 2000 0 0
								11000 4120 1500 0 0
								11000 4130 1000 1 0>;
			};
			strategy_soc_range_mid {
				strategy_temp_little_cold =	<11000 4140 1300 0 0
								11000 4150 1000 1 0>;
				strategy_temp_cool =		<11000 4080 1700 0 0
								11000 4080 1500 0 0
								11000 4180 1000 1 0>;
				strategy_temp_little_cool =	<11000 4080 3000 0 0
								11000 4080 2500 0 0
								11000 4080 2000 0 0
								11000 4180 1700 0 0
								11000 4180 1500 0 0
								11000 4520 1000 1 0>;
				strategy_temp_little_cool_high = <11000 4180 3000 0 0
								11000 4180 2500 0 0
								11000 4180 2000 0 0
								11000 4510 1700 0 0
								11000 4510 1500 0 0
								11000 4520 1000 1 0>;
				strategy_temp_normal_low =	<11000 4510 3500 0 0
								11000 4510 3000 0 0
								11000 4510 2500 0 0
								11000 4510 2000 0 0
								11000 4510 1500 0 0
								11000 4520 1000 1 0>;
				strategy_temp_normal_high =	<11000 4490 4000 0 0
								11000 4490 3500 0 0
								11000 4490 3000 0 0
								11000 4490 2500 0 0
								11000 4490 2000 0 0
								11000 4490 1500 0 0
								11000 4500 1000 1 0>;
				strategy_temp_warm =		<11000 4130 1000 1 0>;
			};
			strategy_soc_range_mid_high {
				strategy_temp_little_cold =	<11000 4150 1000 1 0>;
				strategy_temp_cool =		<11000 4080 1500 0 0
								11000 4180 1000 1 0>;
				strategy_temp_little_cool =	<11000 4080 2000 0 0
								11000 4180 1700 0 0
								11000 4180 1500 0 0
								11000 4520 1000 1 0>;
				strategy_temp_little_cool_high = <11000 4180 2000 0 0
								11000 4510 1700 0 0
								11000 4510 1500 0 0
								11000 4520 1000 1 0>;
				strategy_temp_normal_low =	<11000 4510 2500 0 0
								11000 4510 2000 0 0
								11000 4510 1500 0 0
								11000 4520 1000 1 0>;
				strategy_temp_normal_high =	<11000 4490 2500 0 0
								11000 4490 2000 0 0
								11000 4490 1500 0 0
								11000 4500 1000 1 0>;
				strategy_temp_warm =		<11000 4130 1000 1 0>;
			};
			strategy_soc_range_high {
				strategy_temp_little_cold =	<11000 4150 1000 1 0>;
				strategy_temp_cool =		<11000 4500 1000 1 0>;
				strategy_temp_little_cool =	<11000 4500 1000 1 0>;
				strategy_temp_little_cool_high = <11000 4500 1000 1 0>;
				strategy_temp_normal_low =	<11000 4500 1000 1 0>;
				strategy_temp_normal_high =	<11000 4475 1000 1 0>;
				strategy_temp_warm =		<11000 4130 1000 1 0>;
			};
		};

		ufcs_charge_oplus_strategy {
			oplus,temp_type = <OPLUS_STRATEGY_USE_SHELL_TEMP>;
			oplus,soc_range = <0 20 35 55 75 85 90>;
			oplus,temp_range = <0 50 120 160 210 350 440 510>;

			strategy_soc_range_min {
				strategy_temp_little_cold =	<11000 4150 1300 0 0
								11000 4150 1000 0 0
								11000 4570 500 1 0>;
				strategy_temp_cool =		<11000 4080 1700 0 0
								11000 4080 1500 0 0
								11000 4180 1000 0 0
								11000 4560 700 0 0
								11000 4570 500 1 0>;
				strategy_temp_little_cool =	<11000 4080 3500 0 0
								11000 4080 3000 0 0
								11000 4080 2500 0 0
								11000 4080 2000 0 0
								11000 4180 1700 0 0
								11000 4180 1500 0 0
								11000 4560 1000 0 0
								11000 4570 600 1 0>;
				strategy_temp_little_cool_high = <11000 4080 4200 0 0
								11000 4080 4000 0 0
								11000 4180 3500 0 0
								11000 4180 3000 0 0
								11000 4180 2500 0 0
								11000 4180 2000 0 0
								11000 4560 1700 0 0
								11000 4560 1500 0 0
								11000 4560 1000 0 0
								11000 4570 600 1 0>;
				strategy_temp_normal_low =	<11000 4100 10950 30 0
								11000 4120 10200 180 0
								11000 4120 10000 0 0
								11000 4120 9100 0 0
								11000 4120 9000 0 0
								11000 4330 8900 0 0
								11000 4330 8500 0 0
								11000 4330 8000 0 0
								11000 4330 7500 330 0
								11000 4470 7100 0 0
								11000 4470 7000 0 0
								11000 4470 6500 0 0
								11000 4530 6200 0 0
								11000 4530 6000 0 0
								11000 4530 5500 0 0
								11000 4560 5300 0 0
								11000 4560 5000 0 0
								11000 4560 4500 0 0
								11000 4560 4000 0 0
								11000 4560 3500 0 0
								11000 4560 3000 0 0
								11000 4560 2500 0 0
								11000 4560 2000 0 0
								11000 4560 1500 0 0
								11000 4570 1000 1 0>;
				strategy_temp_normal_high =	<11000 4100 10950 30 0
								11000 4120 10200 180 0
								11000 4120 10000 0 0
								11000 4120 9100 0 0
								11000 4120 9000 0 0
								11000 4330 8900 0 0
								11000 4330 8500 0 0
								11000 4330 8000 0 0
								11000 4330 7500 330 0
								11000 4470 7100 0 0
								11000 4470 7000 0 0
								11000 4470 6500 0 0
								11000 4530 6200 0 0
								11000 4530 6000 0 0
								11000 4530 5500 0 0
								11000 4560 5300 0 0
								11000 4560 5000 0 0
								11000 4560 4500 0 0
								11000 4560 4000 0 0
								11000 4560 3500 0 0
								11000 4560 3000 0 0
								11000 4560 2500 0 0
								11000 4560 2000 0 0
								11000 4570 1800 1 0>;
				strategy_temp_warm =		<11000 4120 2000 0 0
								11000 4120 1500 0 0
								11000 4120 1000 0 0
								11000 4130 500 1 0>;
			};
			strategy_soc_range_low {
				strategy_temp_little_cold =	<11000 4150 1300 0 0
								11000 4150 1000 0 0
								11000 4570 500 1 0>;
				strategy_temp_cool =		<11000 4080 1700 0 0
								11000 4080 1500 0 0
								11000 4180 1000 0 0
								11000 4560 700 0 0
								11000 4570 500 1 0>;
				strategy_temp_little_cool =	<11000 4080 3500 0 0
								11000 4080 3000 0 0
								11000 4080 2500 0 0
								11000 4080 2000 0 0
								11000 4180 1700 0 0
								11000 4180 1500 0 0
								11000 4560 1000 0 0
								11000 4570 600 1 0>;
				strategy_temp_little_cool_high = <11000 4080 4200 0 0
								11000 4080 4000 0 0
								11000 4180 3500 0 0
								11000 4180 3000 0 0
								11000 4180 2500 0 0
								11000 4180 2000 0 0
								11000 4560 1700 0 0
								11000 4560 1500 0 0
								11000 4560 1000 0 0
								11000 4570 600 1 0>;
				strategy_temp_normal_low =	<11000 4100 10950 30 0
								11000 4120 10200 180 0
								11000 4120 10000 0 0
								11000 4120 9100 0 0
								11000 4120 9000 0 0
								11000 4330 8900 0 0
								11000 4330 8500 0 0
								11000 4330 8000 0 0
								11000 4330 7500 330 0
								11000 4470 7100 0 0
								11000 4470 7000 0 0
								11000 4470 6500 0 0
								11000 4530 6200 0 0
								11000 4530 6000 0 0
								11000 4530 5500 0 0
								11000 4560 5300 0 0
								11000 4560 5000 0 0
								11000 4560 4500 0 0
								11000 4560 4000 0 0
								11000 4560 3500 0 0
								11000 4560 3000 0 0
								11000 4560 2500 0 0
								11000 4560 2000 0 0
								11000 4560 1500 0 0
								11000 4570 1000 1 0>;
				strategy_temp_normal_high =	<11000 4100 10950 30 0
								11000 4120 10200 180 0
								11000 4120 10000 0 0
								11000 4120 9100 0 0
								11000 4120 9000 0 0
								11000 4330 8900 0 0
								11000 4330 8500 0 0
								11000 4330 8000 0 0
								11000 4330 7500 330 0
								11000 4470 7100 0 0
								11000 4470 7000 0 0
								11000 4470 6500 0 0
								11000 4530 6200 0 0
								11000 4530 6000 0 0
								11000 4530 5500 0 0
								11000 4560 5300 0 0
								11000 4560 5000 0 0
								11000 4560 4500 0 0
								11000 4560 4000 0 0
								11000 4560 3500 0 0
								11000 4560 3000 0 0
								11000 4560 2500 0 0
								11000 4560 2000 0 0
								11000 4570 1800 1 0>;
				strategy_temp_warm =		<11000 4120 2000 0 0
								11000 4120 1500 0 0
								11000 4120 1000 0 0
								11000 4130 500 1 0>;
			};
			strategy_soc_range_mid_low {
				strategy_temp_little_cold =	<11000 4150 1000 0 0
								11000 4570 500 1 0>;
				strategy_temp_cool =		<11000 4080 1700 0 0
								11000 4080 1500 0 0
								11000 4180 1000 0 0
								11000 4560 700 0 0
								11000 4570 500 1 0>;
				strategy_temp_little_cool =	<11000 4080 3500 0 0
								11000 4080 3000 0 0
								11000 4080 2500 0 0
								11000 4080 2000 0 0
								11000 4180 1700 0 0
								11000 4180 1500 0 0
								11000 4560 1000 0 0
								11000 4570 600 1 0>;
				strategy_temp_little_cool_high = <11000 4080 4200 0 0
								11000 4080 4000 0 0
								11000 4180 3500 0 0
								11000 4180 3000 0 0
								11000 4180 2500 0 0
								11000 4180 2000 0 0
								11000 4560 1700 0 0
								11000 4560 1500 0 0
								11000 4560 1000 0 0
								11000 4570 600 1 0>;
				strategy_temp_normal_low =	<11000 4100 10950 30 0
								11000 4120 10200 180 0
								11000 4120 10000 0 0
								11000 4120 9100 0 0
								11000 4120 9000 0 0
								11000 4330 8900 0 0
								11000 4330 8500 0 0
								11000 4330 8000 0 0
								11000 4330 7500 330 0
								11000 4470 7100 0 0
								11000 4470 7000 0 0
								11000 4470 6500 0 0
								11000 4530 6200 0 0
								11000 4530 6000 0 0
								11000 4530 5500 0 0
								11000 4560 5300 0 0
								11000 4560 5000 0 0
								11000 4560 4500 0 0
								11000 4560 4000 0 0
								11000 4560 3500 0 0
								11000 4560 3000 0 0
								11000 4560 2500 0 0
								11000 4560 2000 0 0
								11000 4560 1500 0 0
								11000 4570 1000 1 0>;
				strategy_temp_normal_high =	<11000 4100 10950 30 0
								11000 4120 10200 180 0
								11000 4120 10000 0 0
								11000 4120 9100 0 0
								11000 4120 9000 0 0
								11000 4330 8900 0 0
								11000 4330 8500 0 0
								11000 4330 8000 0 0
								11000 4330 7500 330 0
								11000 4470 7100 0 0
								11000 4470 7000 0 0
								11000 4470 6500 0 0
								11000 4530 6200 0 0
								11000 4530 6000 0 0
								11000 4530 5500 0 0
								11000 4560 5300 0 0
								11000 4560 5000 0 0
								11000 4560 4500 0 0
								11000 4560 4000 0 0
								11000 4560 3500 0 0
								11000 4560 3000 0 0
								11000 4560 2500 0 0
								11000 4560 2000 0 0
								11000 4570 1800 1 0>;
				strategy_temp_warm =		<11000 4120 2000 0 0
								11000 4120 1500 0 0
								11000 4120 1000 0 0
								11000 4130 500 1 0>;
			};
			strategy_soc_range_mid {
				strategy_temp_little_cold =	<11000 4150 1000 0 0
								11000 4570 500 1 0>;
				strategy_temp_cool =		<11000 4080 1700 0 0
								11000 4080 1500 0 0
								11000 4180 1000 0 0
								11000 4560 700 0 0
								11000 4570 500 1 0>;
				strategy_temp_little_cool =	<11000 4080 3500 0 0
								11000 4080 3000 0 0
								11000 4080 2500 0 0
								11000 4080 2000 0 0
								11000 4180 1700 0 0
								11000 4180 1500 0 0
								11000 4560 1000 0 0
								11000 4570 600 1 0>;
				strategy_temp_little_cool_high = <11000 4080 4000 0 0
								11000 4180 3500 0 0
								11000 4180 3000 0 0
								11000 4180 2500 0 0
								11000 4180 2000 0 0
								11000 4560 1700 0 0
								11000 4560 1500 0 0
								11000 4560 1000 0 0
								11000 4570 600 1 0>;
				strategy_temp_normal_low =	<11000 4560 4500 0 0
								11000 4560 4000 0 0
								11000 4560 3500 0 0
								11000 4560 3000 0 0
								11000 4560 2500 0 0
								11000 4560 2000 0 0
								11000 4560 1500 0 0
								11000 4570 1000 1 0>;
				strategy_temp_normal_high =	<11000 4560 5000 0 0
								11000 4560 4500 0 0
								11000 4560 4000 0 0
								11000 4560 3500 0 0
								11000 4560 3000 0 0
								11000 4560 2500 0 0
								11000 4560 2000 0 0
								11000 4570 1800 1 0>;
				strategy_temp_warm =		<11000 4130 1000 1 0>;
			};
			strategy_soc_range_mid_high {
				strategy_temp_little_cold =	<11000 4150 1000 0 0
								11000 4570 500 1 0>;
				strategy_temp_cool =		<11000 4080 1700 0 0
								11000 4080 1500 0 0
								11000 4180 1000 0 0
								11000 4560 700 0 0
								11000 4570 500 1 0>;
				strategy_temp_little_cool =	<11000 4080 3000 0 0
								11000 4080 2500 0 0
								11000 4080 2000 0 0
								11000 4180 1700 0 0
								11000 4180 1500 0 0
								11000 4560 1000 0 0
								11000 4570 600 1 0>;
				strategy_temp_little_cool_high = <11000 4180 3000 0 0
								11000 4180 2500 0 0
								11000 4180 2000 0 0
								11000 4560 1700 0 0
								11000 4560 1500 0 0
								11000 4560 1000 0 0
								11000 4570 600 1 0>;
				strategy_temp_normal_low =	<11000 4560 3500 0 0
								11000 4560 3000 0 0
								11000 4560 2500 0 0
								11000 4560 2000 0 0
								11000 4560 1500 0 0
								11000 4570 1000 1 0>;
				strategy_temp_normal_high =	<11000 4560 3500 0 0
								11000 4560 3000 0 0
								11000 4560 2500 0 0
								11000 4560 2000 0 0
								11000 4570 1800 1 0>;
				strategy_temp_warm =		<11000 4130 1000 1 0>;
			};
			strategy_soc_range_high {
				strategy_temp_little_cold =	<11000 4150 1000 0 0
								11000 4570 500 1 0>;
				strategy_temp_cool =		<11000 4080 1500 0 0
								11000 4180 1000 0 0
								11000 4560 700 0 0
								11000 4570 500 1 0>;
				strategy_temp_little_cool =	<11000 4180 1700 0 0
								11000 4180 1500 0 0
								11000 4560 1000 0 0
								11000 4570 600 1 0>;
				strategy_temp_little_cool_high = <11000 4560 1700 0 0
								11000 4560 1500 0 0
								11000 4560 1000 0 0
								11000 4570 600 1 0>;
				strategy_temp_normal_low =	<11000 4560 2000 0 0
								11000 4560 1500 0 0
								11000 4570 1000 1 0>;
				strategy_temp_normal_high =	<11000 4560 2000 0 0
								11000 4570 1800 1 0>;
				strategy_temp_warm =		<11000 4130 1000 1 0>;
			};
		};

		oplus,impedance_node {
			ufcs_input_impedance: ufcs_input_impedance {
				node_name = "ufcs_mos";
				default_impedance_mohm = <0>;
				default_curr_ma = <11000>;
				current_drop_table = <
					125 10000
					130 8000
					190 5000
					250 4000
					340 3000
					380 2000
					480 0
				>;
			};
		};
	};
};

&soc {
	oplus_ufcs_impedance_check: oplus,ufcs_impedance_check {
		compatible = "oplus,impedance_check";

		oplus,impedance_unit {
			oplus_ufcs_impedance_unit: oplus,ufcs_impedance_unit {
				uint_name = "ufcs";
				default_curr_ma = <11000>;
				impedance_node = <&ufcs_input_impedance>;
			};
		};
	};
};
&soc {
	oplus_chg_plc: oplus,plc_charge {
		compatible = "oplus,plc_charge";
		oplus,plc_soc = <90>;
		oplus,plc_support_timeout;
		oplus,plc_strategy-data = <&buck_simple_strategy>;
		oplus,plc_strategy-names = "default";

		oplus_ufcs_step_strategy: oplus_ufcs_step_strategy {
			oplus,strategy_type = <PLC_STRATEGY_STEP>;
		};

		cp_2t1_simple_strategy: cp_2t1_simple_strategy {
			oplus,strategy_type = <PLC_STRATEGY_SIMPLE>;
			oplus,strategy_data {
				strategy_curr_ma = <1000 1500>;
			};
		};

		cp_1t1_simple_strategy: cp_1t1_simple_strategy {
			oplus,strategy_type = <PLC_STRATEGY_SIMPLE>;
			oplus,strategy_data {
				strategy_curr_ma = <2000 3000>;
			};
		};

		buck_simple_strategy: buck_simple_strategy {
			oplus,strategy_type = <PLC_STRATEGY_SIMPLE>;
		};
	};
};

//#endif OPLUS_FEATURE_CHG_BASIC /*for ufcs config*/

#include "oplus-chg-24851-pps.dtsi"

//#endif OPLUS_FEATURE_CHG_BASIC

